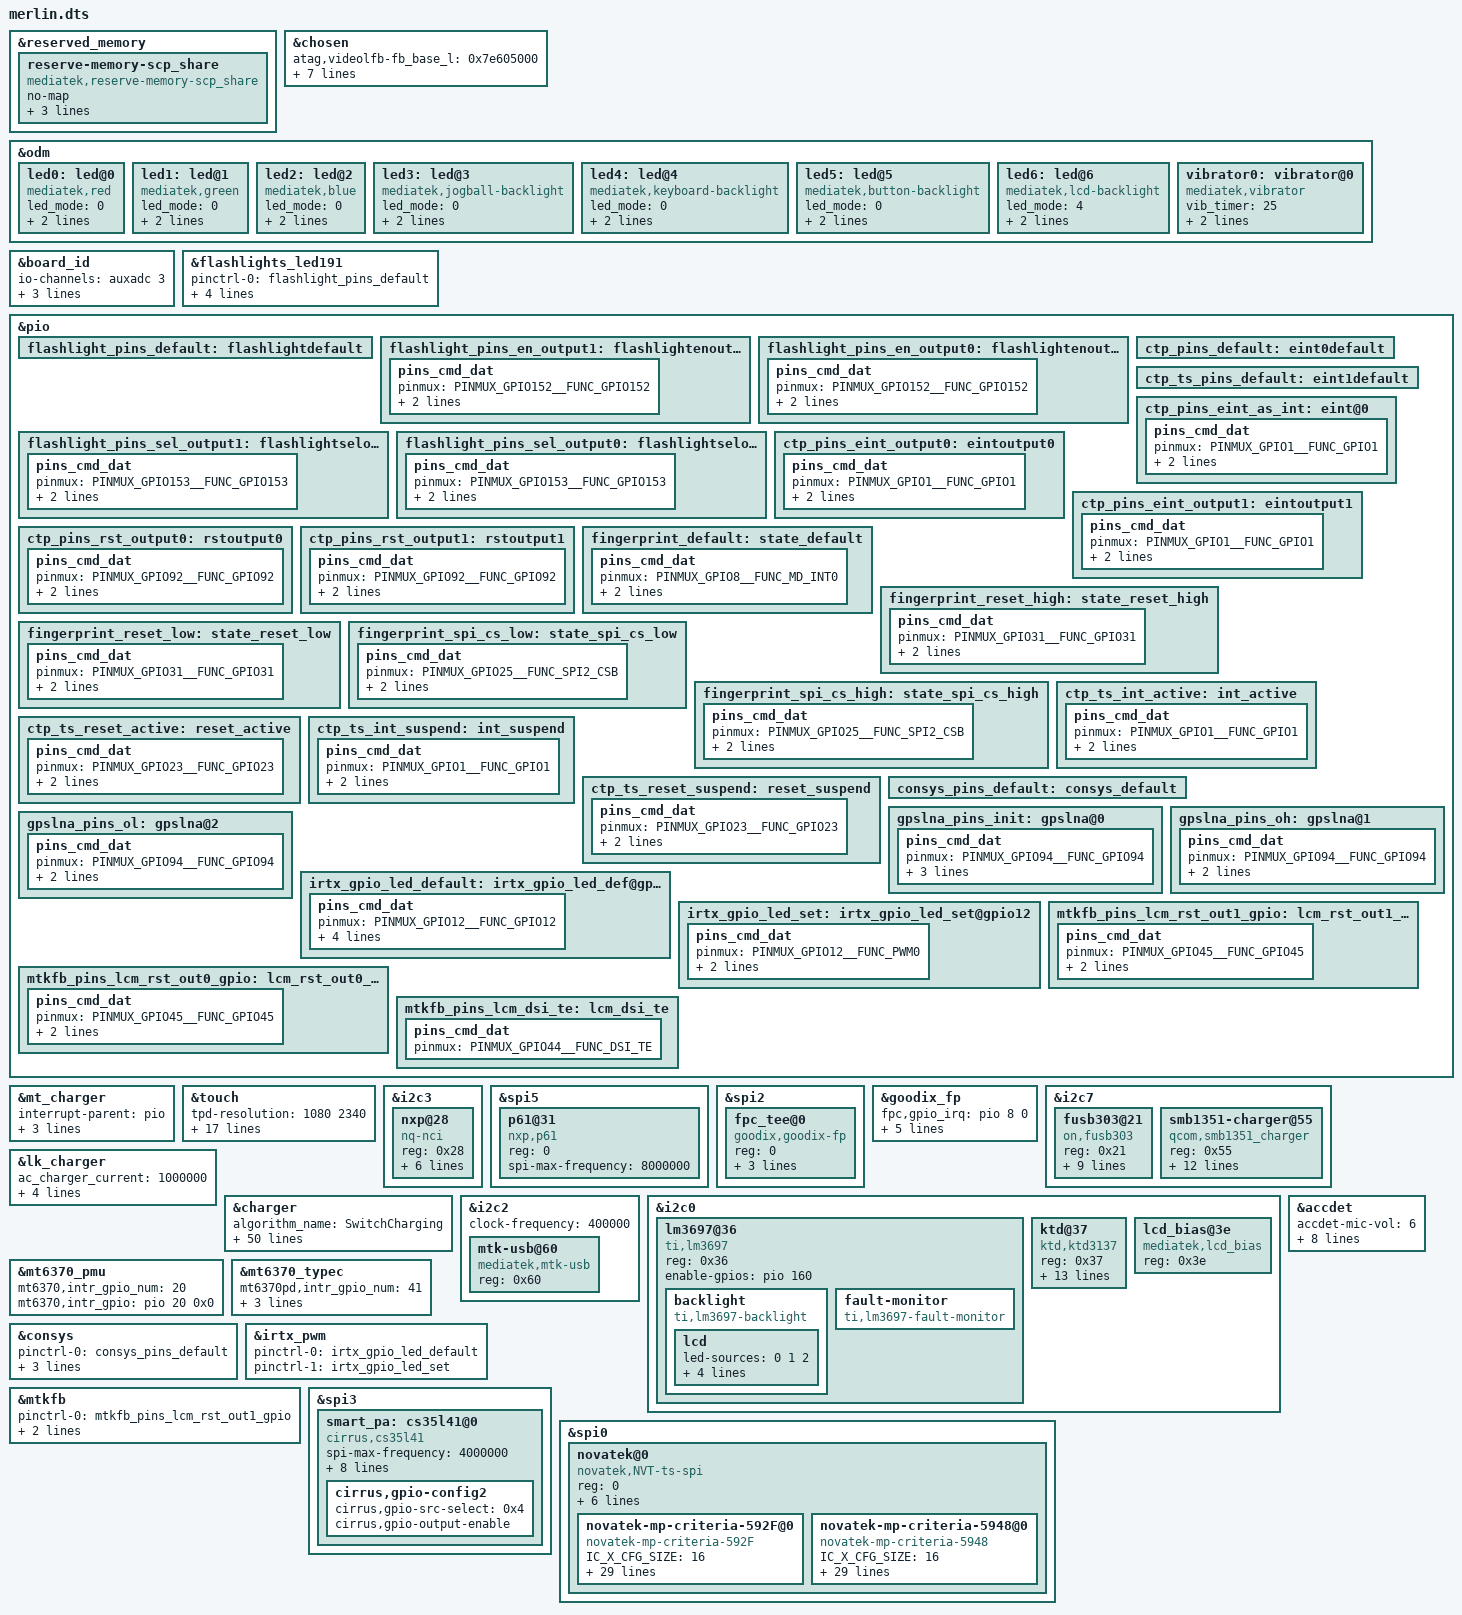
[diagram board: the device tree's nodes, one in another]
/*
 * Copyright (C) 2019 MediaTek Inc.
 *
 * This program is free software; you can redistribute it and/or modify
 * it under the terms of the GNU General Public License version 2 as
 * published by the Free Software Foundation.
 *
 * This program is distributed in the hope that it will be useful,
 * but WITHOUT ANY WARRANTY; without even the implied warranty of
 * MERCHANTABILITY or FITNESS FOR A PARTICULAR PURPOSE.
 * See http://www.gnu.org/licenses/gpl-2.0.html for more details.
 */

/dts-v1/;
/plugin/;
#include <dt-bindings/interrupt-controller/irq.h>
#include <dt-bindings/interrupt-controller/arm-gic.h>
#include <dt-bindings/pinctrl/mt6768-pinfunc.h>

&reserved_memory {
	reserve-memory-scp_share {
		compatible = "mediatek,reserve-memory-scp_share";
		no-map;
		size = <0 0x00d00000>;
		alignment = <0 0x1000000>;
		alloc-ranges = <0 0x40000000 0 0x50000000>;
	};
};

/* chosen */
&chosen {

	atag,videolfb-fb_base_l = <0x7e605000>;
	atag,videolfb-fb_base_h = <0x0>;
	atag,videolfb-islcmfound = <1>;
	atag,videolfb-islcm_inited = <0>;
	atag,videolfb-fps= <6000>;
	atag,videolfb-vramSize= <0x017e8000>;
	atag,videolfb-lcmname=
		"hx83112b_fhdp_dsi_cmd_auo_rt5081_drv";
};

&odm {
	led0:led@0 {
		compatible = "mediatek,red";
		led_mode = <0>;
		data = <1>;
		pwm_config = <0 0 0 0 0>;
	};
	led1:led@1 {
		compatible = "mediatek,green";
		led_mode = <0>;
		data = <1>;
		pwm_config = <0 0 0 0 0>;
	};
	led2:led@2 {
		compatible = "mediatek,blue";
		led_mode = <0>;
		data = <1>;
		pwm_config = <0 0 0 0 0>;
	};
	led3:led@3 {
		compatible = "mediatek,jogball-backlight";
		led_mode = <0>;
		data = <1>;
		pwm_config = <0 0 0 0 0>;
	};
	led4:led@4 {
		compatible = "mediatek,keyboard-backlight";
		led_mode = <0>;
		data = <1>;
		pwm_config = <0 0 0 0 0>;
	};
	led5:led@5 {
		compatible = "mediatek,button-backlight";
		led_mode = <0>;
		data = <1>;
		pwm_config = <0 0 0 0 0>;
	};
	led6:led@6 {
		compatible = "mediatek,lcd-backlight";
		led_mode = <4>;
		data = <1>;
		pwm_config = <0 3 0 0 0>;
	};
	vibrator0:vibrator@0 {
		compatible = "mediatek,vibrator";
		vib_timer = <25>;
		vib_limit = <9>;
		vib_vol= <10>;
	};
};

&board_id {
	io-channels = <&auxadc 3>;
	io-channel-names = "board_id-channel";
	hw_id-gpios = <&pio 158 0>;
	board_id2-gpios = <&pio 5 0>;
	board_id3-gpios = <&pio 6 0>;
	status = "okay";
};
/*
&board_id {
	io-channels = <&auxadc 3>;
	io-channel-names = "board_id-channel";
	status = "okay";
};
*/

/* flashlight start */
&flashlights_led191 {
	pinctrl-names = "default", "hw_ch0_high",
		"hw_ch0_low", "hw_ch1_high",
		"hw_ch1_low";
	pinctrl-0 = <&flashlight_pins_default>;
	pinctrl-1 = <&flashlight_pins_en_output1>;
	pinctrl-2 = <&flashlight_pins_en_output0>;
	pinctrl-3 = <&flashlight_pins_sel_output1>;
	pinctrl-4 = <&flashlight_pins_sel_output0>;
	status = "okay";
};
&pio {
	flashlight_pins_default: flashlightdefault {
	};
	flashlight_pins_en_output1: flashlightenoutput1 {
		pins_cmd_dat {
			pinmux = <PINMUX_GPIO152__FUNC_GPIO152>;
			slew-rate = <1>;
			output-high;
		};
	};
	flashlight_pins_en_output0: flashlightenoutput0 {
		pins_cmd_dat {
			pinmux = <PINMUX_GPIO152__FUNC_GPIO152>;
			slew-rate = <1>;
			output-low;
		};
	};
	flashlight_pins_sel_output1: flashlightseloutput1 {
		pins_cmd_dat {
			pinmux = <PINMUX_GPIO153__FUNC_GPIO153>;
			slew-rate = <1>;
			output-high;
		};
	};
	flashlight_pins_sel_output0: flashlightseloutput0 {
		pins_cmd_dat {
			pinmux = <PINMUX_GPIO153__FUNC_GPIO153>;
			slew-rate = <1>;
			output-low;
		};
	};
};
/* flashlight end*/

&mt_charger {
	interrupt-parent = <&pio>;
	reverse-gpio = <&pio 91 0>;
	pinctrl-names = "reverse_high", "reverse_low";
	pinctrl-0 = <&reverse_high>;
	pinctrl-1 = <&reverse_low>;
};
/* TOUCH start */
&touch {
	tpd-resolution = <1080 2340>;
	use-tpd-button = <0>;
	tpd-key-num = <3>;
	tpd-key-local= <139 172 158 0>;
	tpd-key-dim-local = <90 883 100 40 230
				883 100 40 370 883 100 40 0 0 0 0>;
	tpd-max-touch-num = <10>;
	tpd-filter-enable = <0>;
	tpd-filter-pixel-density = <168>;
	tpd-filter-custom-prameters = <0 0 0 0 0 0 0 0 0 0 0 0>;
	tpd-filter-custom-speed = <0 0 0>;
	pinctrl-names = "default", "state_eint_as_int",
		"state_eint_output0", "state_eint_output1",
		"state_rst_output0", "state_rst_output1";
	pinctrl-0 = <&ctp_pins_default>;
	pinctrl-1 = <&ctp_pins_eint_as_int>;
	pinctrl-2 = <&ctp_pins_eint_output0>;
	pinctrl-3 = <&ctp_pins_eint_output1>;
	pinctrl-4 = <&ctp_pins_rst_output0>;
	pinctrl-5 = <&ctp_pins_rst_output1>;
	status = "okay";
};
&pio {
	ctp_pins_default: eint0default {
	};
	ctp_ts_pins_default: eint1default {
	};
	ctp_pins_eint_as_int: eint@0 {
		pins_cmd_dat {
			pinmux = <PINMUX_GPIO1__FUNC_GPIO1>;
			slew-rate = <0>;
			bias-disable;
		};
	};
	ctp_pins_eint_output0: eintoutput0 {
		pins_cmd_dat {
			pinmux = <PINMUX_GPIO1__FUNC_GPIO1>;
			slew-rate = <1>;
			output-low;
		};
	};
	ctp_pins_eint_output1: eintoutput1 {
		pins_cmd_dat {
			pinmux = <PINMUX_GPIO1__FUNC_GPIO1>;
			slew-rate = <1>;
			output-high;
	};
	};
	ctp_pins_rst_output0: rstoutput0 {
		pins_cmd_dat {
				pinmux = <PINMUX_GPIO92__FUNC_GPIO92>;
				slew-rate = <1>;
				output-low;
			};
	};
	ctp_pins_rst_output1: rstoutput1 {
		pins_cmd_dat {
				pinmux = <PINMUX_GPIO92__FUNC_GPIO92>;
				slew-rate = <1>;
				output-high;
		};
	};

};
/* TOUCH end */
&i2c3 {
	status = "okay";
	nxp@28 {
		compatible = "nq-nci";
		reg = <0x28>;
		nq-irq = <&pio 9 0x00>;
		interrupt-parent = <&pio>;
		interrupts = <9 IRQ_TYPE_LEVEL_HIGH 9 0>;
		nq-ven = <&pio 159 0x0>;
		nq-firm = <&pio 17 0x0>;
		nq-clkreq = <&pio 11 0x0>;
		//nq-esepwr = <&tlmm 42 0x00>;
		interrupt-names = "irq_nfc";
	};

};
/* add goodix fingerprint start*/

&spi5 {
	#address-cells = <1>;
	#size-cells = <0>;
	p61@31 {
		compatible = "nxp,p61";
		reg = <0>;
		spi-max-frequency = <8000000>;
		status = "okay";
	};
};


&spi2 {
	status = "ok";
	#address-cells = <1>;
	#size-cells = <0>;
	fpc_tee@0 {
		compatible = "goodix,goodix-fp";
		reg = <0>;
		fpc,enable-wakeup;
		spi-max-frequency = <10000000>;
		netlink-event = <30>;
		status = "okay";
	};
};

&goodix_fp {
	fpc,gpio_irq = <&pio 8 0>;
	pinctrl-names = "default", "reset_high", "reset_low", "spi_cs_low", "spi_cs_high";
	pinctrl-0 = <&fingerprint_default>;
	pinctrl-1 = <&fingerprint_reset_high>;
	pinctrl-2 = <&fingerprint_reset_low>;
	pinctrl-3 = <&fingerprint_spi_cs_low>;
	pinctrl-4 = <&fingerprint_spi_cs_high>;
	status = "okay";
};

&pio {
	fingerprint_default: state_default {
		pins_cmd_dat {
			pinmux = <PINMUX_GPIO8__FUNC_MD_INT0>;
			slew-rate = <0>;
			bias-disable;
		};
	};
	fingerprint_reset_high: state_reset_high {
		pins_cmd_dat {
			pinmux = <PINMUX_GPIO31__FUNC_GPIO31>;
			slew-rate = <1>;
			output-high;
		};
	};
	fingerprint_reset_low: state_reset_low {
		pins_cmd_dat {
			pinmux = <PINMUX_GPIO31__FUNC_GPIO31>;
			slew-rate = <1>;
			output-low;
		};
	};

	fingerprint_spi_cs_low: state_spi_cs_low {
		pins_cmd_dat {
			pinmux = <PINMUX_GPIO25__FUNC_SPI2_CSB>;
			slew-rate = <1>;
			output-low;
		};
	};
	fingerprint_spi_cs_high: state_spi_cs_high {
		pins_cmd_dat {
			pinmux = <PINMUX_GPIO25__FUNC_SPI2_CSB>;
			slew-rate = <1>;
			output-high;
		};
	};

	ctp_ts_int_active: int_active {
		pins_cmd_dat {
			pinmux = <PINMUX_GPIO1__FUNC_GPIO1>;
			slew-rate = <0>;
			bias-pull-up = <11>;
		};
	};
	ctp_ts_reset_active: reset_active {
		pins_cmd_dat {
			pinmux = <PINMUX_GPIO23__FUNC_GPIO23>;
			slew-rate = <1>;
			output-high;
		};
	};
	ctp_ts_int_suspend: int_suspend {
		pins_cmd_dat {
			pinmux = <PINMUX_GPIO1__FUNC_GPIO1>;
			slew-rate = <1>;
			output-low;
		};
	};
	ctp_ts_reset_suspend: reset_suspend {
		pins_cmd_dat {
			pinmux = <PINMUX_GPIO23__FUNC_GPIO23>;
			slew-rate = <1>;
			output-low;
		};
	};
};
/* add goodix fingerprint end*/

&i2c7 {
	fusb303@21 {
		status = "ok";
		compatible = "on,fusb303";
		reg = <0x21>;
		interrupt-parent = <&pio>;
		interrupts = <41 0x2>;
		fusb303,int-gpio = <&pio 41 0>;
		fusb303,init-mode = <20>;			/* trysnk, DRP */
		fusb303,host-current = <2>;			/* 180uA host current */
		fusb303,drp-toggle-time =  <1>;			/* 70ms */
		fusb303,drp-duty-time = <0>;			/* 60 duty time */
		fusb303,autosink-threshold = <1>;		/* 3P1V */
		fusb303,cc-debounce-time = <3>;			/* 150ms */
	};
};


&i2c7 {
	smb1351-charger@55 {
		compatible = "qcom,smb1351_charger";
		reg = <0x55>;
		interrupt-parent = <&pio>;
		interrupts = <20 IRQ_TYPE_EDGE_FALLING 20 0>;
		qcom,recharge-disabled;
		qcom,bc12_supported;
		/* qcom,smb1351_susp = <&pio 21 0x0>; */
		/* mi,connect_therm = <&pio 127 0x0>; */

		charger_name = "primary_chg";
		/*charger_name = "secondary_chg";*/
		ichg = <1800000>; /* uA */
		mivr = <4500000>; /* uV */
		cv = <4396000>; /* uV */
		ieoc = <200000>; /* uA */
		safety_timer = <12>; /* hour */
		en_st; /* safety timer */
		/* en_te; */
		en_wdt;
	};

};
&lk_charger  {
	/* charging current */
	ac_charger_current = <1000000>;
	non_std_ac_charger_current = <1000000>;

	/* battery temperature protection */
	temp_t4_threshold = <60>;
	temp_t3_threshold = <45>;
	temp_t1_threshold = <0>;
};

&charger {
	algorithm_name = "SwitchCharging";

	set_cap_delay = <10>;
	enable_sw_jeita;
	battery_cv = <4460000>;
	usb_charger_current_suspend = <0>;
	usb_charger_current_unconfigured = <70000>;
	usb_charger_current_configured = <500000>;
	usb_charger_current = <500000>;
	ac_charger_current = <2050000>;
	ac_charger_input_current = <2050000>;
	non_std_ac_charger_current = <1000000>;
	charging_host_charger_current = <1500000>;
	apple_1_0a_charger_current = <650000>;
	apple_2_1a_charger_current = <800000>;
	ta_ac_charger_current = <2050000>;
	hvdcp_charger_current = <3000000>;

	pd_vbus_upper_bound = <9000000>;


	/* sw jeita */
	jeita_temp_above_t4_cv = <4100000>;
	jeita_temp_t3_to_t4_cv = <4100000>;
	jeita_temp_t2_to_t3_cv = <4460000>;
	jeita_temp_t1_to_t2_cv = <4460000>;
	jeita_temp_t0_to_t1_cv = <4460000>;
	jeita_temp_below_t0_cv = <4460000>;


	jeita_temp_t3_to_t4_cc = <2500000>;
	jeita_temp_t2_to_t3_cc = <3000000>;
	jeita_temp_t1_to_t2_cc = <2500000>;
	jeita_temp_t0_to_t1_cc = <1000000>;

	temp_t4_thres = <60>;
	temp_t4_thres_minus_x_degree = <58>;
	temp_t3_thres = <45>;
	temp_t3_thres_minus_x_degree = <43>;
	temp_t2_thres = <10>;
	temp_t2_thres_plus_x_degree = <8>;
	temp_t1_thres = <5>;
	temp_t1_thres_plus_x_degree = <4>;
	temp_t0_thres = <0>;
	temp_t0_thres_plus_x_degree = <0>;
	temp_neg_10_thres = <0>;

	/* battery temperature protection */
	enable_min_charge_temp;
	min_charge_temp = <0>;
	min_charge_temp_plus_x_degree = <2>;
	max_charge_temp = <60>;
	max_charge_temp_minus_x_degree = <58>;

	qcom,thermal-mitigation-dcp
		= <1800000 1800000 1800000 1800000 1800000 1800000 1800000
		1800000 1800000 1800000 1800000 1800000 1600000 1400000
		1200000 1000000>;
	qcom,thermal-mitigation-qc3
		= <2700000 2570000 2400000 2270000 2120000 1965000 1820000
		1650000 1500000 1375000 1225000 1100000 975000 825000
		675000 475000>;
	qcom,thermal-mitigation-qc2
		= <1625000 1625000 1625000 1625000 1625000 1525000 1425000
		1325000 1225000 1125000 1025500 925000 825000 725000
		625000 525000>;
	qcom,thermal-mitigation-pd-base
		= <3000000 2800000 2600000 2400000 2200000 2000000 1800000
		1600000 1600000 1400000 1200000 1100000 1000000 900000
		752500 525000>;
};




&i2c2 {
	clock-frequency = <400000>;

	mtk-usb@60 {
		compatible = "mediatek,mtk-usb";
		reg = <0x60>;
		status = "okay";
	};
};

&i2c0 {
	lm3697@36 {
		compatible = "ti,lm3697";
		reg = <0x36>;

		status = "okay";
		enable-gpios = <&pio 160 0>;

		backlight {
			compatible = "ti,lm3697-backlight";

			lcd {
				led-sources = <0 1 2>;
				ramp-up-msec = <200>;
				ramp-down-msec = <200>;
				pwm-period = <0>;
				default-brightness-level = <255>;
			};
		};
		fault-monitor {
			compatible = "ti,lm3697-fault-monitor";
		};
	};

	ktd@37 {
	compatible = "ktd,ktd3137";
	reg = <0x37>;
	status = "okay";
        /*ktd,pwm-mode; */
	ktd,using-lsb = <1>;
	ktd,pwm-frequency = <100>;
	ktd,bl-fscal-led = <0x98>;/*default 20.2mA*/
	ktd,turn-on-ramp = <0>;
	ktd,turn-off-ramp = <0>;
	ktd,pwm-trans-dim = <0>;
	ktd,i2c-trans-dim = <0>;
	ktd,bl-channel = <2>;
	ktd,ovp-level = <32>;/*default 32v*/
	ktd,switching-frequency = <1000>; /*default 1000kHz*/
	ktd,inductor-current = <2600>; //default 2600mA
	ktd,linear_ramp = <1>; /*default is exponential*/
	ktd,linear_backlight = <1>; /*default is exponential*/
    };

	lcd_bias@3e {
		compatible = "mediatek,lcd_bias";
		reg = <0x3e>;
		status = "okay";
	};
};

/* accdet start */
&accdet {
	/* accdet micbias voltage: 0x07,2.7v;0x05,2.5v;0x02,1.9v */
	accdet-mic-vol = <6>;
	headset-mode-setting = <0x500 0x500 1 0x1f0 0x800 0x800 0x20 0x44>;
	accdet-plugout-debounce = <1>;
	/*1:ACC mode, 2:low cost without in bias, 6:low cost with in bias*/
	accdet-mic-mode = <1>;
	/* eint_level_trigger: 8,LEVEL_LOW(DEF) ;4,LV_HIGH;others,LV_LOW */
	headset-eint-level-pol = <8>;
	/*0--MD_MAX--UP_MAX--DW_MAX*/
	headset-three-key-threshold = <0 80 220 400>;
	headset-three-key-threshold-CDD = <0 121 192 600>;
	/*0--MD_MAX--VOICE_MAX--UP_MAX--DW_MAX*/
	headset-four-key-threshold = <0 58 121 192 400>;
	status = "okay";
};
/* accdet end */

&mt6370_pmu {
	mt6370,intr_gpio_num = <20>; /* direct defined GPIO num */
	mt6370,intr_gpio = <&pio 20 0x0>;
};
&mt6370_typec {
	mt6370pd,intr_gpio_num = <41>; /* direct defined GPIO num */
	mt6370pd,intr_gpio = <&pio 41 0x0>;
	mt6370pd,usb_switch_gpio_num = <91>; /* direct defined GPIO num */
	mt6370pd,usb_switch_gpio = <&pio 91 0x0>;
};

/* CONSYS GPIO standardization */
&pio {
	consys_pins_default: consys_default {
	};
	gpslna_pins_init: gpslna@0 {
		pins_cmd_dat {
			pinmux = <PINMUX_GPIO94__FUNC_GPIO94>;
			slew-rate = <0>;
			bias-disable;
			output-low;
		};
	};
	gpslna_pins_oh: gpslna@1 {
		pins_cmd_dat {
			pinmux = <PINMUX_GPIO94__FUNC_GPIO94>;
			slew-rate = <1>;
			output-high;
		};
	};
	gpslna_pins_ol: gpslna@2 {
		pins_cmd_dat {
			pinmux = <PINMUX_GPIO94__FUNC_GPIO94>;
			slew-rate = <1>;
			output-low;
		};
	};
};
&consys {
	pinctrl-names = "default", "gps_lna_state_init",
		"gps_lna_state_oh", "gps_lna_state_ol";
	pinctrl-0 = <&consys_pins_default>;
	pinctrl-1 = <&gpslna_pins_init>;
	pinctrl-2 = <&gpslna_pins_oh>;
	pinctrl-3 = <&gpslna_pins_ol>;
	status = "okay";
};
/* CONSYS end */

/* IRTX GPIO Start */
&irtx_pwm {
	pinctrl-names = "irtx_gpio_led_default", "irtx_gpio_led_set";
	pinctrl-0 = <&irtx_gpio_led_default>;
	pinctrl-1 = <&irtx_gpio_led_set>;
	status = "okay";
};
&pio {
	/* IRTX GPIO Settings -Start */
	/* default: GPIO0, output, high */
	irtx_gpio_led_default:irtx_gpio_led_def@gpio12 {
		pins_cmd_dat {
			pinmux = <PINMUX_GPIO12__FUNC_GPIO12>;
			slew-rate = <1>;
			bias-disable;
			output-low;
			input-schmitt-enable = <0>;
		};
	};

	irtx_gpio_led_set:irtx_gpio_led_set@gpio12 {
		pins_cmd_dat {
			pinmux = <PINMUX_GPIO12__FUNC_PWM0>;
			slew-rate = <1>;
			output-high;
		};
	};
}; /* IRTX GPIO Settings -End */

/* DISPSYS GPIO standardization */
&pio {
	mtkfb_pins_lcm_rst_out1_gpio: lcm_rst_out1_gpio {
		pins_cmd_dat {
			pinmux = <PINMUX_GPIO45__FUNC_GPIO45>;
			slew-rate = <1>;
			output-high;
		};
	};

	mtkfb_pins_lcm_rst_out0_gpio: lcm_rst_out0_gpio {
		pins_cmd_dat {
			pinmux = <PINMUX_GPIO45__FUNC_GPIO45>;
			slew-rate = <1>;
			output-low;
		};
	};

	mtkfb_pins_lcm_dsi_te: lcm_dsi_te {
		pins_cmd_dat {
			pinmux = <PINMUX_GPIO44__FUNC_DSI_TE>;
		};
	};
};

&mtkfb {
	pinctrl-names =
		"lcm_rst_out1_gpio", "lcm_rst_out0_gpio",
		"mode_te_te";
	pinctrl-0 = <&mtkfb_pins_lcm_rst_out1_gpio>;
	pinctrl-1 = <&mtkfb_pins_lcm_rst_out0_gpio>;
	pinctrl-2 = <&mtkfb_pins_lcm_dsi_te>;
	status = "okay";
};

&spi3 {
    status = "okay";
    smart_pa:cs35l41@0 {
	       compatible = "cirrus,cs35l41";
		spi-max-frequency = <4000000>;
		reg = <0>;
		reset-gpio = <&pio 79 0>;
		interrupt-parent = <&gpio>;
		interrupts = <80 8>;
		irq-gpio = <&pio 80 0>;
		cirrus,boost-peak-milliamp = <4500>;
		cirrus,boost-ind-nanohenry = <1000>;
		cirrus,boost-cap-microfarad = <15>;
		cirrus,gpio-config2 {
		    cirrus,gpio-src-select = <0x4>;
		    cirrus,gpio-output-enable;
		    };
	   };
};

&spi0 {
	status = "ok";


	/* Novatek device tree node */
	novatek@0 {
		compatible = "novatek,NVT-ts-spi","focaltech,fts";
		reg = <0>; //Same as CS ID
		status = "ok";

		spi-max-frequency = <8000000>;
		//4800000,9600000,15000000,19200000;ft8719 max limit 8M
		novatek,reset-gpio = <&pio 92 0x00>;
		novatek,irq-gpio = <&pio 1 0x2001>;

		/* 525 */
		//novatek,swrst-n8-addr = <0x01F01A>;

		/* 672A, 525B, 675, 526 */
		novatek,swrst-n8-addr = <0x03F0FE>;
		novatek,spi-rd-fast-addr = <0x03F310>;

		/* MP */
		novatek,mp-support-dt;

		novatek-mp-criteria-592F@0 {
			#address-cells = <1>;
			#size-cells = <0>;
			compatible = "novatek-mp-criteria-592F";

			/* MP Config */
			IC_X_CFG_SIZE = <16>;
			IC_Y_CFG_SIZE = <36>;
			IC_KEY_CFG_SIZE = <4>;
			X_Channel = <16>;
			Y_Channel = <36>;
			AIN_X = <0 1 2 3 4 5 6 7 8 9 10 11 12 13 14 15>;
			AIN_Y = <0 1 2 3 4 5 6 7 8 9 10 11 12 13 14 15 16 17
						18 19 20 21 22 23 24 25 26 27 28 29 30 31 32 33 34 35>;
			AIN_KEY = <0 1 2 0xFF>;

			/* MP Criteria */
			PS_Config_Lmt_Short_Rawdata_P = <
				14000	14000	14000	14000	14000	14000	14000	14000	14000	14000	14000	14000	14000	14000	14000	14000
				14000	14000	14000	14000	14000	14000	14000	14000	14000	14000	14000	14000	14000	14000	14000	14000
				14000	14000	14000	14000	14000	14000	14000	14000	14000	14000	14000	14000	14000	14000	14000	14000
				14000	14000	14000	14000	14000	14000	14000	14000	14000	14000	14000	14000	14000	14000	14000	14000
				14000	14000	14000	14000	14000	14000	14000	14000	14000	14000	14000	14000	14000	14000	14000	14000
				14000	14000	14000	14000	14000	14000	14000	14000	14000	14000	14000	14000	14000	14000	14000	14000
				14000	14000	14000	14000	14000	14000	14000	14000	14000	14000	14000	14000	14000	14000	14000	14000
				14000	14000	14000	14000	14000	14000	14000	14000	14000	14000	14000	14000	14000	14000	14000	14000
				14000	14000	14000	14000	14000	14000	14000	14000	14000	14000	14000	14000	14000	14000	14000	14000
				14000	14000	14000	14000	14000	14000	14000	14000	14000	14000	14000	14000	14000	14000	14000	14000
				14000	14000	14000	14000	14000	14000	14000	14000	14000	14000	14000	14000	14000	14000	14000	14000
				14000	14000	14000	14000	14000	14000	14000	14000	14000	14000	14000	14000	14000	14000	14000	14000
				14000	14000	14000	14000	14000	14000	14000	14000	14000	14000	14000	14000	14000	14000	14000	14000
				14000	14000	14000	14000	14000	14000	14000	14000	14000	14000	14000	14000	14000	14000	14000	14000
				14000	14000	14000	14000	14000	14000	14000	14000	14000	14000	14000	14000	14000	14000	14000	14000
				14000	14000	14000	14000	14000	14000	14000	14000	14000	14000	14000	14000	14000	14000	14000	14000
				14000	14000	14000	14000	14000	14000	14000	14000	14000	14000	14000	14000	14000	14000	14000	14000
				14000	14000	14000	14000	14000	14000	14000	14000	14000	14000	14000	14000	14000	14000	14000	14000
				14000	14000	14000	14000	14000	14000	14000	14000	14000	14000	14000	14000	14000	14000	14000	14000
				14000	14000	14000	14000	14000	14000	14000	14000	14000	14000	14000	14000	14000	14000	14000	14000
				14000	14000	14000	14000	14000	14000	14000	14000	14000	14000	14000	14000	14000	14000	14000	14000
				14000	14000	14000	14000	14000	14000	14000	14000	14000	14000	14000	14000	14000	14000	14000	14000
				14000	14000	14000	14000	14000	14000	14000	14000	14000	14000	14000	14000	14000	14000	14000	14000
				14000	14000	14000	14000	14000	14000	14000	14000	14000	14000	14000	14000	14000	14000	14000	14000
				14000	14000	14000	14000	14000	14000	14000	14000	14000	14000	14000	14000	14000	14000	14000	14000
				14000	14000	14000	14000	14000	14000	14000	14000	14000	14000	14000	14000	14000	14000	14000	14000
				14000	14000	14000	14000	14000	14000	14000	14000	14000	14000	14000	14000	14000	14000	14000	14000
				14000	14000	14000	14000	14000	14000	14000	14000	14000	14000	14000	14000	14000	14000	14000	14000
				14000	14000	14000	14000	14000	14000	14000	14000	14000	14000	14000	14000	14000	14000	14000	14000
				14000	14000	14000	14000	14000	14000	14000	14000	14000	14000	14000	14000	14000	14000	14000	14000
				14000	14000	14000	14000	14000	14000	14000	14000	14000	14000	14000	14000	14000	14000	14000	14000
				14000	14000	14000	14000	14000	14000	14000	14000	14000	14000	14000	14000	14000	14000	14000	14000
				14000	14000	14000	14000	14000	14000	14000	14000	14000	14000	14000	14000	14000	14000	14000	14000
				14000	14000	14000	14000	14000	14000	14000	14000	14000	14000	14000	14000	14000	14000	14000	14000
				14000	14000	14000	14000	14000	14000	14000	14000	14000	14000	14000	14000	14000	14000	14000	14000
				14000	14000	14000	14000	14000	14000	14000	14000	14000	14000	14000	14000	14000	14000	14000	14000
				14008 14008 14008>;

			PS_Config_Lmt_Short_Rawdata_N = <
				11000	11000	11000	11000	11000	11000	11000	11000	11000	11000	11000	11000	11000	11000	11000	11000
				11000	11000	11000	11000	11000	11000	11000	11000	11000	11000	11000	11000	11000	11000	11000	11000
				11000	11000	11000	11000	11000	11000	11000	11000	11000	11000	11000	11000	11000	11000	11000	11000
				11000	11000	11000	11000	11000	11000	11000	11000	11000	11000	11000	11000	11000	11000	11000	11000
				11000	11000	11000	11000	11000	11000	11000	11000	11000	11000	11000	11000	11000	11000	11000	11000
				11000	11000	11000	11000	11000	11000	11000	11000	11000	11000	11000	11000	11000	11000	11000	11000
				11000	11000	11000	11000	11000	11000	11000	11000	11000	11000	11000	11000	11000	11000	11000	11000
				11000	11000	11000	11000	11000	11000	11000	11000	11000	11000	11000	11000	11000	11000	11000	11000
				11000	11000	11000	11000	11000	11000	11000	11000	11000	11000	11000	11000	11000	11000	11000	11000
				11000	11000	11000	11000	11000	11000	11000	11000	11000	11000	11000	11000	11000	11000	11000	11000
				11000	11000	11000	11000	11000	11000	11000	11000	11000	11000	11000	11000	11000	11000	11000	11000
				11000	11000	11000	11000	11000	11000	11000	11000	11000	11000	11000	11000	11000	11000	11000	11000
				11000	11000	11000	11000	11000	11000	11000	11000	11000	11000	11000	11000	11000	11000	11000	11000
				11000	11000	11000	11000	11000	11000	11000	11000	11000	11000	11000	11000	11000	11000	11000	11000
				11000	11000	11000	11000	11000	11000	11000	11000	11000	11000	11000	11000	11000	11000	11000	11000
				11000	11000	11000	11000	11000	11000	11000	11000	11000	11000	11000	11000	11000	11000	11000	11000
				11000	11000	11000	11000	11000	11000	11000	11000	11000	11000	11000	11000	11000	11000	11000	11000
				11000	11000	11000	11000	11000	11000	11000	11000	11000	11000	11000	11000	11000	11000	11000	11000
				11000	11000	11000	11000	11000	11000	11000	11000	11000	11000	11000	11000	11000	11000	11000	11000
				11000	11000	11000	11000	11000	11000	11000	11000	11000	11000	11000	11000	11000	11000	11000	11000
				11000	11000	11000	11000	11000	11000	11000	11000	11000	11000	11000	11000	11000	11000	11000	11000
				11000	11000	11000	11000	11000	11000	11000	11000	11000	11000	11000	11000	11000	11000	11000	11000
				11000	11000	11000	11000	11000	11000	11000	11000	11000	11000	11000	11000	11000	11000	11000	11000
				11000	11000	11000	11000	11000	11000	11000	11000	11000	11000	11000	11000	11000	11000	11000	11000
				11000	11000	11000	11000	11000	11000	11000	11000	11000	11000	11000	11000	11000	11000	11000	11000
				11000	11000	11000	11000	11000	11000	11000	11000	11000	11000	11000	11000	11000	11000	11000	11000
				11000	11000	11000	11000	11000	11000	11000	11000	11000	11000	11000	11000	11000	11000	11000	11000
				11000	11000	11000	11000	11000	11000	11000	11000	11000	11000	11000	11000	11000	11000	11000	11000
				11000	11000	11000	11000	11000	11000	11000	11000	11000	11000	11000	11000	11000	11000	11000	11000
				11000	11000	11000	11000	11000	11000	11000	11000	11000	11000	11000	11000	11000	11000	11000	11000
				11000	11000	11000	11000	11000	11000	11000	11000	11000	11000	11000	11000	11000	11000	11000	11000
				11000	11000	11000	11000	11000	11000	11000	11000	11000	11000	11000	11000	11000	11000	11000	11000
				11000	11000	11000	11000	11000	11000	11000	11000	11000	11000	11000	11000	11000	11000	11000	11000
				11000	11000	11000	11000	11000	11000	11000	11000	11000	11000	11000	11000	11000	11000	11000	11000
				11000	11000	11000	11000	11000	11000	11000	11000	11000	11000	11000	11000	11000	11000	11000	11000
				11000	11000	11000	11000	11000	11000	11000	11000	11000	11000	11000	11000	11000	11000	11000	11000
				10000 10000 10000>;

			PS_Config_Lmt_Open_Rawdata_P = <
				2899	65535	3065	3097	3064	3077	3046	3068	3037	3083	3053	3088	3070	3122	3055	2029
				2937	2764	3008	3049	3013	3035	3004	3021	3014	3061	3031	3068	3053	3103	3083	3079
				3083	2838	3020	3058	3022	3045	3011	3030	3023	3069	3037	3073	3061	3110	3086	3115
				3055	3054	3013	3051	3017	3040	3003	3022	3014	3056	3028	3063	3054	3100	3077	3126
				3049	3067	3027	3065	3025	3048	3014	3032	3018	3060	3035	3065	3058	3106	3077	3134
				3063	3073	3034	3070	3031	3055	3018	3039	3031	3072	3049	3082	3070	3114	3091	3134
				3072	3096	3054	3089	3049	3073	3036	3054	3046	3081	3060	3092	3079	3121	3097	3128
				3074	3098	3054	3091	3053	3078	3037	3055	3049	3081	3060	3093	3082	3120	3097	3114
				3101	3100	3054	3087	3046	3072	3031	3046	3042	3073	3054	3088	3073	3117	3089	3129
				3102	3108	3059	3092	3055	3081	3036	3056	3046	3069	3044	3087	3072	3110	3089	3122
				3091	3105	3053	3083	3042	3069	3026	3051	3056	3082	3055	3100	3086	3125	3100	3136
				3089	3103	3061	3092	3050	3077	3035	3059	3051	3074	3049	3094	3077	3115	3086	3136
				3075	3115	3070	3100	3060	3089	3045	3069	3073	3098	3075	3120	3101	3143	3115	3128
				3087	3116	3074	3103	3064	3091	3044	3075	3072	3094	3073	3119	3097	3136	3111	3136
				3093	3119	3084	3112	3070	3098	3055	3088	3086	3114	3089	3133	3111	3150	3119	3140
				3094	3106	3073	3103	3060	3086	3049	3077	3075	3100	3078	3124	3101	3141	3106	3120
				3101	3106	3075	3101	3058	3083	3046	3086	3086	3114	3092	3136	3112	3153	3114	3144
				3083	3105	3074	3101	3054	3082	3045	3083	3067	3091	3070	3117	3089	3129	3088	3150
				3075	3089	3058	3083	3045	3072	3030	3065	3089	3117	3098	3141	3112	3153	3112	3129
				3060	3106	3074	3103	3063	3089	3051	3088	3094	3116	3097	3141	3111	3149	3110	3136
				3059	3101	3068	3096	3056	3083	3044	3083	3068	3094	3072	3116	3091	3130	3087	3128
				3082	3079	3049	3074	3032	3063	3026	3059	3068	3097	3072	3115	3086	3128	3084	3117
				3069	3075	3045	3072	3030	3060	3026	3063	3060	3091	3068	3106	3077	3116	3079	3108
				3048	3074	3041	3068	3025	3053	3018	3060	3050	3083	3055	3096	3065	3103	3064	3102
				3039	3056	3025	3056	3013	3044	3011	3049	3041	3074	3048	3088	3059	3093	3056	3107
				3046	3049	3022	3050	3009	3041	3011	3046	3039	3073	3044	3084	3053	3088	3053	3091
				3030	3060	3030	3055	3014	3042	3013	3051	3048	3087	3053	3091	3061	3096	3060	3074
				3026	3028	2998	3026	2983	3014	2984	3022	3017	3055	3026	3067	3037	3073	3040	3061
				3027	3027	2998	3026	2983	3013	2984	3020	3003	3039	3008	3048	3020	3055	3018	3061
				2994	3008	2983	3009	2967	2999	2970	3006	2987	3023	2993	3035	3008	3040	3008	3037
				2993	2994	2966	2995	2954	2985	2957	2992	2983	3022	2994	3034	3007	3042	3011	3034
				2768	2976	2745	2978	2735	2969	2733	2974	2759	3002	2767	3011	2780	3018	2781	3009
				2759	2762	2736	2763	2725	2753	2724	2755	2754	2788	2763	2800	2774	2807	2776	2800
				2748	2767	2739	2764	2724	2752	2725	2757	2735	2768	2740	2781	2754	2787	2757	2827
				2678	2745	2713	2741	2701	2727	2703	2733	2706	2743	2719	2760	2733	2766	2735	2736
				1630	2717	2733	2763	2719	2748	2730	2753	2741	2773	2745	2788	2762	2791	2721	1675
				5120 5120 5120>;

			PS_Config_Lmt_Open_Rawdata_N = <
				1666	(-65535)	1762	1780	1761	1768	1751	1763	1746	1772	1754	1775	1765	1795	1756	1166
				1688	1589	1729	1752	1732	1744	1727	1736	1733	1760	1742	1763	1754	1784	1772	1770
				1772	1631	1735	1757	1737	1750	1730	1741	1738	1764	1746	1766	1760	1787	1773	1790
				1756	1755	1732	1754	1734	1747	1726	1737	1733	1757	1741	1760	1755	1781	1768	1797
				1752	1762	1740	1762	1738	1752	1733	1743	1735	1759	1744	1762	1757	1785	1768	1801
				1760	1766	1743	1765	1742	1756	1735	1746	1742	1765	1752	1771	1765	1789	1776	1801
				1765	1779	1755	1776	1752	1766	1745	1755	1751	1770	1759	1777	1770	1794	1780	1797
				1767	1781	1755	1776	1754	1769	1746	1756	1752	1770	1759	1778	1771	1793	1780	1789
				1782	1781	1755	1774	1751	1765	1742	1751	1749	1766	1755	1775	1766	1792	1776	1798
				1783	1787	1758	1777	1756	1770	1745	1757	1751	1764	1749	1774	1765	1787	1776	1795
				1776	1784	1754	1772	1749	1764	1739	1754	1757	1771	1756	1781	1773	1796	1781	1803
				1776	1784	1760	1777	1753	1768	1744	1758	1754	1767	1752	1779	1768	1790	1773	1803
				1768	1790	1765	1781	1759	1776	1750	1764	1766	1781	1768	1793	1782	1806	1790	1797
				1774	1791	1767	1784	1761	1776	1749	1768	1765	1779	1766	1792	1780	1803	1788	1803
				1778	1792	1773	1789	1765	1781	1756	1775	1773	1789	1776	1800	1788	1811	1792	1805
				1779	1785	1766	1784	1759	1773	1752	1768	1768	1781	1769	1795	1782	1806	1785	1793
				1782	1785	1768	1782	1757	1772	1751	1773	1773	1789	1777	1803	1789	1812	1789	1807
				1772	1784	1767	1782	1755	1771	1750	1772	1762	1776	1765	1792	1776	1798	1775	1811
				1768	1776	1757	1772	1750	1765	1741	1762	1776	1792	1781	1806	1789	1812	1789	1798
				1759	1785	1767	1784	1760	1776	1754	1775	1779	1791	1780	1806	1788	1810	1787	1803
				1758	1782	1763	1779	1757	1772	1749	1772	1763	1779	1765	1791	1776	1799	1774	1797
				1771	1770	1752	1767	1743	1760	1739	1758	1763	1780	1765	1790	1773	1797	1773	1792
				1764	1768	1750	1765	1741	1759	1739	1760	1759	1776	1763	1785	1768	1791	1770	1787
				1752	1767	1748	1763	1738	1754	1735	1759	1753	1772	1756	1779	1762	1784	1761	1783
				1746	1757	1738	1757	1732	1749	1730	1752	1748	1767	1752	1775	1758	1778	1757	1786
				1751	1752	1737	1753	1730	1748	1730	1751	1746	1766	1749	1773	1754	1775	1754	1776
				1741	1759	1741	1756	1733	1749	1732	1754	1752	1774	1754	1776	1760	1779	1759	1767
				1739	1741	1723	1739	1714	1733	1715	1737	1734	1756	1739	1762	1746	1766	1747	1760
				1740	1740	1723	1739	1714	1732	1715	1735	1726	1746	1729	1752	1735	1756	1735	1760
				1721	1729	1714	1730	1706	1724	1707	1727	1716	1738	1720	1744	1729	1747	1729	1746
				1720	1721	1705	1722	1697	1716	1700	1719	1714	1737	1721	1743	1728	1749	1730	1743
				1591	1711	1578	1711	1572	1706	1570	1709	1586	1725	1590	1730	1597	1735	1598	1730
				1586	1587	1573	1588	1566	1582	1565	1584	1583	1603	1588	1609	1595	1614	1595	1609
				1579	1590	1574	1589	1565	1581	1566	1584	1572	1591	1575	1598	1583	1602	1584	1624
				1539	1578	1560	1576	1552	1568	1554	1570	1555	1576	1562	1587	1570	1589	1572	1573
				937		1562	1570	1588	1562	1579	1569	1582	1576	1594	1578	1603	1587	1604	1564	962
				50 50 50>;
				
			PS_Config_Lmt_FW_Rawdata_P = <
				2166	65535	2130	2107	2115	2124	2099	2157	2157	2134	2139	2154	2157	2126	2149	2150
				2182	2142	2161	2184	2162	2127	2162	2142	2135	2155	2155	2127	2128	2124	2164	2126
				2185	2123	2168	2133	2139	2135	2137	2151	2085	2207	2162	2188	2153	2170	2177	2124
				2164	2139	2138	2123	2139	2131	2097	2124	2116	2182	2118	2110	2145	2118	2172	2112
				2165	2106	2149	2145	2107	2104	2114	2162	2091	2165	2174	2145	2154	2150	2124	2172
				2135	2164	2110	2134	2119	2154	2116	2135	2116	2099	2224	2111	2104	2092	2130	2133
				2097	2178	2114	2122	2119	2106	2106	2123	2177	2131	2145	2162	2164	2178	2170	2184
				2133	2176	2124	2146	2128	2146	2123	2143	2122	2139	2137	2112	2124	2118	2147	2207
				2124	2118	2131	2146	2107	2131	2133	2147	2176	2104	2146	2184	2174	2207	2166	2176
				2124	2153	2110	2141	2135	2126	2157	2138	2208	2138	2151	2151	2177	2174	2174	2176
				2146	2191	2123	2143	2141	2149	2158	2187	2169	2153	2103	2207	2203	2088	2205	2101
				2208	2187	2181	2160	2200	2214	2133	2161	2135	2143	2119	2164	2170	2137	2151	2122
				2093	2130	2134	2096	2112	2122	2138	2184	2216	2234	2178	2092	2088	2112	2134	2120
				2115	2134	2112	2158	2122	2147	2151	2120	2142	2155	2127	2168	2164	2170	2173	2203
				2106	2143	2242	2226	2234	2137	2126	2114	2185	2149	2137	2184	2199	2172	2154	2181
				2199	2147	2143	2126	2108	2126	2143	2120	2185	2168	2160	2097	2160	2161	2173	2139
				2107	2124	2150	2141	2108	2123	2139	2161	2142	2173	2182	2124	2139	2142	2112	2089
				2108	2158	2162	2182	2153	2174	2169	2110	2214	2178	2111	2064	2096	2073	2107	2205
				2147	2178	2164	2160	2185	2153	2131	2150	2185	2155	2124	2145	2147	2142	2155	2169
				2146	2123	2151	2131	2119	2114	2110	2153	2145	2058	2235	2228	2191	2204	2207	2189
				2120	2137	2155	2133	2126	2168	2151	2142	2177	2204	2196	2160	2220	2197	2181	2155
				2145	2138	2124	2119	2160	2157	2174	2189	2145	2158	2134	2139	2138	2118	2083	2119
				2143	2166	2172	2150	2151	2138	2116	2127	2104	2085	2108	2142	2134	2185	2149	2185
				2160	2166	2188	2162	2195	2135	2149	2201	2166	2137	2161	2145	2155	2138	2150	2149
				2180	2204	2188	2164	2215	2084	2093	2164	2145	2110	2151	2119	2112	2124	2119	2134
				2138	2120	2124	2120	2177	2147	2145	2164	2166	2184	2154	2165	2149	2155	2165	2173
				2181	2162	2143	2184	2153	2147	2120	2147	2145	2170	2096	2100	2161	2142	2182	2174
				2180	2151	2169	2124	2126	2169	2130	2123	2119	2155	2120	2118	2127	2141	2149	2170
				2154	2157	2162	2180	2154	2170	2126	2169	2178	2151	2166	2149	2162	2157	2111	2141
				2207	2134	2141	2161	2120	2166	2138	2157	2123	2135	2110	2160	2143	2162	2135	2127
				2128	2216	2191	2192	2169	2177	2154	2158	2193	2205	2174	2169	2164	2195	2134	2133
				2177	2184	2145	2207	2131	2130	2150	2158	2149	2189	2134	2157	2154	2155	2150	2097
				2166	2178	2133	2141	2118	2178	2176	2157	2131	2162	2122	2160	2141	2161	2130	2161
				2174	2146	2147	2111	2149	2200	2139	2138	2147	2143	2138	2176	2177	2142	2177	2153
				2107	2147	2176	2196	2182	2141	2137	2104	2142	2096	2085	2077	2118	2164	2150	2155
				2188	2104	2135	2089	2099	2097	2147	2164	2160	2137	2116	2124	2124	2155	2155	2188
				2560 2560 2560>;

			PS_Config_Lmt_FW_Rawdata_N = <
				1043	(-65535)	1025	1014	1018	1023	1010	1038	1038	1027	1030	1037	1038	1023	1034	1035
				1051	1031	1040	1051	1041	1024	1041	1031	1028	1038	1038	1024	1025	1023	1041	1023
				1052	1022	1043	1027	1030	1028	1028	1036	1004	1062	1041	1053	1036	1045	1048	1023
				1041	1030	1029	1022	1030	1026	1010	1023	1019	1051	1019	1015	1032	1019	1045	1017
				1042	1014	1034	1032	1014	1013	1017	1041	1006	1042	1047	1032	1037	1035	1023	1045
				1028	1041	1015	1027	1020	1037	1019	1028	1019	1010	1071	1016	1013	1007	1025	1027
				1010	1049	1017	1021	1020	1014	1014	1022	1048	1026	1032	1041	1041	1049	1045	1051
				1027	1047	1023	1033	1025	1033	1022	1032	1021	1030	1028	1017	1023	1019	1034	1062
				1023	1019	1026	1033	1014	1026	1027	1034	1047	1013	1033	1051	1047	1062	1043	1047
				1023	1036	1015	1030	1028	1023	1038	1029	1063	1029	1036	1036	1048	1047	1047	1047
				1033	1054	1022	1032	1030	1034	1039	1053	1044	1036	1012	1062	1060	1005	1062	1012
				1063	1053	1050	1040	1059	1066	1027	1040	1028	1032	1020	1041	1045	1028	1036	1021
				1008	1025	1027	1009	1017	1021	1029	1051	1067	1075	1049	1007	1005	1017	1027	1021
				1018	1027	1017	1039	1021	1034	1036	1021	1031	1038	1024	1043	1041	1045	1046	1060
				1014	1032	1079	1071	1075	1028	1023	1017	1052	1034	1028	1051	1058	1045	1037	1050
				1058	1034	1032	1023	1015	1023	1032	1021	1052	1043	1040	1010	1040	1040	1046	1030
				1014	1023	1035	1030	1015	1022	1030	1040	1031	1046	1051	1023	1030	1031	1017	1006
				1015	1039	1041	1051	1036	1047	1044	1015	1066	1049	1016	993	1009	998	1014	1062
				1034	1049	1041	1040	1052	1036	1026	1035	1052	1038	1023	1032	1034	1031	1038	1044
				1033	1022	1036	1026	1020	1017	1015	1036	1032	991	1076	1073	1054	1061	1062	1054
				1021	1028	1038	1027	1023	1043	1036	1031	1048	1061	1057	1040	1069	1058	1050	1038
				1032	1029	1023	1020	1040	1038	1047	1054	1032	1039	1027	1030	1029	1019	1002	1020
				1032	1043	1045	1035	1036	1029	1019	1024	1013	1004	1015	1031	1027	1052	1034	1052
				1040	1043	1053	1041	1056	1028	1034	1060	1043	1028	1040	1032	1038	1029	1035	1034
				1049	1061	1053	1041	1066	1003	1008	1041	1032	1015	1036	1020	1017	1023	1020	1027
				1029	1021	1023	1021	1048	1034	1032	1041	1043	1051	1037	1042	1034	1038	1042	1046
				1050	1041	1032	1051	1036	1034	1021	1034	1032	1045	1009	1011	1040	1031	1051	1047
				1049	1036	1044	1023	1023	1044	1025	1022	1020	1038	1021	1019	1024	1030	1034	1045
				1037	1038	1041	1049	1037	1045	1023	1044	1049	1036	1043	1034	1041	1038	1016	1030
				1062	1027	1030	1040	1021	1043	1029	1038	1022	1028	1015	1040	1032	1041	1028	1024
				1025	1067	1054	1055	1044	1048	1037	1039	1056	1062	1047	1044	1041	1056	1027	1027
				1048	1051	1032	1062	1026	1025	1035	1039	1034	1054	1027	1038	1037	1038	1035	1010
				1043	1049	1027	1030	1019	1049	1047	1038	1026	1041	1021	1040	1030	1040	1025	1040
				1047	1033	1034	1016	1034	1059	1030	1029	1034	1032	1029	1047	1048	1031	1048	1036
				1014	1034	1047	1057	1051	1030	1028	1013	1031	1009	1004	1000	1019	1041	1035	1038
				1053	1013	1028	1006	1010	1010	1034	1041	1040	1028	1019	1023	1023	1038	1038	1053
				240 240 240>;

			PS_Config_Lmt_FW_CC_P = <
				107	65535	119	119	119	119	119	119	122	122	121	120	120	119	119	105
				120	107	105	105	106	106	105	106	112	112	110	109	109	109	109	109
				125	106	105	105	105	105	105	105	109	109	107	106	106	106	105	107
				112	107	106	106	106	106	106	106	110	107	107	107	107	107	107	111
				110	107	106	106	105	106	106	106	109	107	106	105	105	105	105	107
				111	109	107	107	107	107	107	107	111	110	110	109	109	109	109	110
				110	106	105	105	105	105	105	105	109	107	107	106	106	106	105	109
				112	107	107	107	107	107	107	107	110	109	110	107	107	107	107	110
				110	107	107	107	106	107	107	107	109	109	109	106	106	107	106	110
				112	109	107	107	107	107	107	107	110	110	110	107	107	107	107	109
				110	106	105	105	105	105	106	106	110	109	109	106	106	107	106	110
				111	105	105	106	105	105	106	107	107	107	107	105	105	105	105	111
				110	106	105	106	105	106	106	107	109	109	109	109	109	109	107	109
				110	107	107	109	109	109	109	110	110	110	110	109	109	107	107	110
				110	105	105	105	105	106	106	109	106	107	107	105	105	106	105	110
				111	107	107	107	107	107	107	110	109	109	109	109	107	107	107	111
				109	107	107	107	107	107	107	109	109	109	107	107	107	107	107	110
				111	107	107	107	107	107	109	110	110	110	110	109	109	109	109	111
				110	105	105	105	105	105	106	106	107	107	106	106	106	106	105	110
				110	107	107	107	107	107	109	110	110	110	109	107	107	107	107	112
				109	106	106	106	106	107	107	107	110	109	107	107	107	106	106	110
				110	109	109	109	109	109	109	109	111	110	110	109	109	110	110	112
				110	106	105	106	105	106	107	107	110	107	107	106	107	106	106	112
				111	107	107	107	107	109	109	110	110	109	107	109	107	107	107	114
				109	106	106	107	106	107	107	109	109	109	107	107	109	107	107	112
				111	109	109	109	109	110	110	111	110	110	109	110	109	110	110	112
				110	106	105	105	105	107	107	107	107	107	107	107	107	107	107	112
				112	107	107	107	107	110	109	110	109	109	109	109	109	109	109	115
				109	107	107	107	107	109	109	110	106	107	106	106	107	107	109	115
				110	110	110	109	109	111	110	111	109	109	109	109	109	109	110	115
				111	106	105	105	105	106	106	107	107	107	107	107	107	107	110	114
				112	109	107	107	107	110	109	110	107	107	107	109	109	110	110	116
				107	107	107	107	106	107	107	110	106	106	107	106	107	107	110	112
				111	109	109	110	109	110	111	111	109	109	109	110	109	110	111	127
				110	106	105	105	105	107	109	109	105	105	106	106	106	106	109	110
				105	119	117	119	119	121	122	122	120	119	120	120	120	120	122	112
				314 314 314>;

			PS_Config_Lmt_FW_CC_N = <
				66	(-65535)	72	72	72	72	72	72	75	75	74	73	73	72	72	64
				73	66	64	64	65	65	64	65	69	69	67	66	66	66	66	66
				76	65	64	64	64	64	64	64	66	66	66	65	65	65	64	66
				69	66	65	65	65	65	65	65	67	66	66	66	66	66	66	68
				67	66	65	65	64	65	65	65	66	66	65	64	64	64	64	66
				68	66	66	66	66	66	66	66	68	67	67	66	66	66	66	67
				67	65	64	64	64	64	64	64	66	66	66	65	65	65	64	66
				69	66	66	66	66	66	66	66	67	66	67	66	66	66	66	67
				67	66	66	66	65	66	66	66	66	66	66	65	65	66	65	67
				69	66	66	66	66	66	66	66	67	67	67	66	66	66	66	66
				67	65	64	64	64	64	65	65	67	66	66	65	65	66	65	67
				68	64	64	65	64	64	65	66	66	66	66	64	64	64	64	68
				67	65	64	65	64	65	65	66	66	66	66	66	66	66	66	66
				67	66	66	66	66	66	66	67	67	67	67	66	66	66	66	67
				67	64	64	64	64	65	65	66	65	66	66	64	64	65	64	67
				68	66	66	66	66	66	66	67	66	66	66	66	66	66	66	68
				66	66	66	66	66	66	66	66	66	66	66	66	66	66	66	67
				68	66	66	66	66	66	66	67	67	67	67	66	66	66	66	68
				67	64	64	64	64	64	65	65	66	66	65	65	65	65	64	67
				67	66	66	66	66	66	66	67	67	67	66	66	66	66	66	69
				66	65	65	65	65	66	66	66	67	66	66	66	66	65	65	67
				67	66	66	66	66	66	66	66	68	67	67	66	66	67	67	69
				67	65	64	65	64	65	66	66	67	66	66	65	66	65	65	69
				68	66	66	66	66	66	66	67	67	66	66	66	66	66	66	69
				66	65	65	66	65	66	66	66	66	66	66	66	66	66	66	69
				68	66	66	66	66	67	67	68	67	67	66	67	66	67	67	69
				67	65	64	64	64	66	66	66	66	66	66	66	66	66	66	69
				69	66	66	66	66	67	66	67	66	66	66	66	66	66	66	70
				66	66	66	66	66	66	66	67	65	66	65	65	66	66	66	70
				67	67	67	66	66	68	67	68	66	66	66	66	66	66	67	70
				68	65	64	64	64	65	65	66	66	66	66	66	66	66	67	69
				69	66	66	66	66	67	66	67	66	66	66	66	66	67	67	71
				66	66	66	66	65	66	66	67	65	65	66	65	66	66	67	69
				68	66	66	67	66	67	68	68	66	66	66	67	66	67	68	78
				67	65	64	64	64	66	66	66	64	64	65	65	65	65	66	67
				64	72	72	72	72	74	75	75	73	72	73	73	73	73	75	69
				0 0 0>;

			PS_Config_Lmt_FW_Diff_P = <
				50	65535	50	50	50	50	50	50	50	50	50	50	50	50	50	50
				50	50	50	50	50	50	50	50	50	50	50	50	50	50	50	50
				50	50	50	50	50	50	50	50	50	50	50	50	50	50	50	50
				50	50	50	50	50	50	50	50	50	50	50	50	50	50	50	50
				50	50	50	50	50	50	50	50	50	50	50	50	50	50	50	50
				50	50	50	50	50	50	50	50	50	50	50	50	50	50	50	50
				50	50	50	50	50	50	50	50	50	50	50	50	50	50	50	50
				50	50	50	50	50	50	50	50	50	50	50	50	50	50	50	50
				50	50	50	50	50	50	50	50	50	50	50	50	50	50	50	50
				50	50	50	50	50	50	50	50	50	50	50	50	50	50	50	50
				50	50	50	50	50	50	50	50	50	50	50	50	50	50	50	50
				50	50	50	50	50	50	50	50	50	50	50	50	50	50	50	50
				50	50	50	50	50	50	50	50	50	50	50	50	50	50	50	50
				50	50	50	50	50	50	50	50	50	50	50	50	50	50	50	50
				50	50	50	50	50	50	50	50	50	50	50	50	50	50	50	50
				50	50	50	50	50	50	50	50	50	50	50	50	50	50	50	50
				50	50	50	50	50	50	50	50	50	50	50	50	50	50	50	50
				50	50	50	50	50	50	50	50	50	50	50	50	50	50	50	50
				50	50	50	50	50	50	50	50	50	50	50	50	50	50	50	50
				50	50	50	50	50	50	50	50	50	50	50	50	50	50	50	50
				50	50	50	50	50	50	50	50	50	50	50	50	50	50	50	50
				50	50	50	50	50	50	50	50	50	50	50	50	50	50	50	50
				50	50	50	50	50	50	50	50	50	50	50	50	50	50	50	50
				50	50	50	50	50	50	50	50	50	50	50	50	50	50	50	50
				50	50	50	50	50	50	50	50	50	50	50	50	50	50	50	50
				50	50	50	50	50	50	50	50	50	50	50	50	50	50	50	50
				50	50	50	50	50	50	50	50	50	50	50	50	50	50	50	50
				50	50	50	50	50	50	50	50	50	50	50	50	50	50	50	50
				50	50	50	50	50	50	50	50	50	50	50	50	50	50	50	50
				50	50	50	50	50	50	50	50	50	50	50	50	50	50	50	50
				50	50	50	50	50	50	50	50	50	50	50	50	50	50	50	50
				50	50	50	50	50	50	50	50	50	50	50	50	50	50	50	50
				50	50	50	50	50	50	50	50	50	50	50	50	50	50	50	50
				50	50	50	50	50	50	50	50	50	50	50	50	50	50	50	50
				50	50	50	50	50	50	50	50	50	50	50	50	50	50	50	50
				50	50	50	50	50	50	50	50	50	50	50	50	50	50	50	50
				75 75 75>;


			PS_Config_Lmt_FW_Diff_N = <
				 (-50)	(-65535)	(-50)	(-50)	(-50)	(-50)	(-50)	(-50)	(-50)	(-50)	(-50)	(-50)	(-50)	(-50)	(-50)	(-50)
				(-50)	(-50)	(-50)	(-50)	(-50)	(-50)	(-50)	(-50)	(-50)	(-50)	(-50)	(-50)	(-50)	(-50)	(-50)	(-50)
				(-50)	(-50)	(-50)	(-50)	(-50)	(-50)	(-50)	(-50)	(-50)	(-50)	(-50)	(-50)	(-50)	(-50)	(-50)	(-50)
				(-50)	(-50)	(-50)	(-50)	(-50)	(-50)	(-50)	(-50)	(-50)	(-50)	(-50)	(-50)	(-50)	(-50)	(-50)	(-50)
				(-50)	(-50)	(-50)	(-50)	(-50)	(-50)	(-50)	(-50)	(-50)	(-50)	(-50)	(-50)	(-50)	(-50)	(-50)	(-50)
				(-50)	(-50)	(-50)	(-50)	(-50)	(-50)	(-50)	(-50)	(-50)	(-50)	(-50)	(-50)	(-50)	(-50)	(-50)	(-50)
				(-50)	(-50)	(-50)	(-50)	(-50)	(-50)	(-50)	(-50)	(-50)	(-50)	(-50)	(-50)	(-50)	(-50)	(-50)	(-50)
				(-50)	(-50)	(-50)	(-50)	(-50)	(-50)	(-50)	(-50)	(-50)	(-50)	(-50)	(-50)	(-50)	(-50)	(-50)	(-50)
				(-50)	(-50)	(-50)	(-50)	(-50)	(-50)	(-50)	(-50)	(-50)	(-50)	(-50)	(-50)	(-50)	(-50)	(-50)	(-50)
				(-50)	(-50)	(-50)	(-50)	(-50)	(-50)	(-50)	(-50)	(-50)	(-50)	(-50)	(-50)	(-50)	(-50)	(-50)	(-50)
				(-50)	(-50)	(-50)	(-50)	(-50)	(-50)	(-50)	(-50)	(-50)	(-50)	(-50)	(-50)	(-50)	(-50)	(-50)	(-50)
				(-50)	(-50)	(-50)	(-50)	(-50)	(-50)	(-50)	(-50)	(-50)	(-50)	(-50)	(-50)	(-50)	(-50)	(-50)	(-50)
				(-50)	(-50)	(-50)	(-50)	(-50)	(-50)	(-50)	(-50)	(-50)	(-50)	(-50)	(-50)	(-50)	(-50)	(-50)	(-50)
				(-50)	(-50)	(-50)	(-50)	(-50)	(-50)	(-50)	(-50)	(-50)	(-50)	(-50)	(-50)	(-50)	(-50)	(-50)	(-50)
				(-50)	(-50)	(-50)	(-50)	(-50)	(-50)	(-50)	(-50)	(-50)	(-50)	(-50)	(-50)	(-50)	(-50)	(-50)	(-50)
				(-50)	(-50)	(-50)	(-50)	(-50)	(-50)	(-50)	(-50)	(-50)	(-50)	(-50)	(-50)	(-50)	(-50)	(-50)	(-50)
				(-50)	(-50)	(-50)	(-50)	(-50)	(-50)	(-50)	(-50)	(-50)	(-50)	(-50)	(-50)	(-50)	(-50)	(-50)	(-50)
				(-50)	(-50)	(-50)	(-50)	(-50)	(-50)	(-50)	(-50)	(-50)	(-50)	(-50)	(-50)	(-50)	(-50)	(-50)	(-50)
				(-50)	(-50)	(-50)	(-50)	(-50)	(-50)	(-50)	(-50)	(-50)	(-50)	(-50)	(-50)	(-50)	(-50)	(-50)	(-50)
				(-50)	(-50)	(-50)	(-50)	(-50)	(-50)	(-50)	(-50)	(-50)	(-50)	(-50)	(-50)	(-50)	(-50)	(-50)	(-50)
				(-50)	(-50)	(-50)	(-50)	(-50)	(-50)	(-50)	(-50)	(-50)	(-50)	(-50)	(-50)	(-50)	(-50)	(-50)	(-50)
				(-50)	(-50)	(-50)	(-50)	(-50)	(-50)	(-50)	(-50)	(-50)	(-50)	(-50)	(-50)	(-50)	(-50)	(-50)	(-50)
				(-50)	(-50)	(-50)	(-50)	(-50)	(-50)	(-50)	(-50)	(-50)	(-50)	(-50)	(-50)	(-50)	(-50)	(-50)	(-50)
				(-50)	(-50)	(-50)	(-50)	(-50)	(-50)	(-50)	(-50)	(-50)	(-50)	(-50)	(-50)	(-50)	(-50)	(-50)	(-50)
				(-50)	(-50)	(-50)	(-50)	(-50)	(-50)	(-50)	(-50)	(-50)	(-50)	(-50)	(-50)	(-50)	(-50)	(-50)	(-50)
				(-50)	(-50)	(-50)	(-50)	(-50)	(-50)	(-50)	(-50)	(-50)	(-50)	(-50)	(-50)	(-50)	(-50)	(-50)	(-50)
				(-50)	(-50)	(-50)	(-50)	(-50)	(-50)	(-50)	(-50)	(-50)	(-50)	(-50)	(-50)	(-50)	(-50)	(-50)	(-50)
				(-50)	(-50)	(-50)	(-50)	(-50)	(-50)	(-50)	(-50)	(-50)	(-50)	(-50)	(-50)	(-50)	(-50)	(-50)	(-50)
				(-50)	(-50)	(-50)	(-50)	(-50)	(-50)	(-50)	(-50)	(-50)	(-50)	(-50)	(-50)	(-50)	(-50)	(-50)	(-50)
				(-50)	(-50)	(-50)	(-50)	(-50)	(-50)	(-50)	(-50)	(-50)	(-50)	(-50)	(-50)	(-50)	(-50)	(-50)	(-50)
				(-50)	(-50)	(-50)	(-50)	(-50)	(-50)	(-50)	(-50)	(-50)	(-50)	(-50)	(-50)	(-50)	(-50)	(-50)	(-50)
				(-50)	(-50)	(-50)	(-50)	(-50)	(-50)	(-50)	(-50)	(-50)	(-50)	(-50)	(-50)	(-50)	(-50)	(-50)	(-50)
				(-50)	(-50)	(-50)	(-50)	(-50)	(-50)	(-50)	(-50)	(-50)	(-50)	(-50)	(-50)	(-50)	(-50)	(-50)	(-50)
				(-50)	(-50)	(-50)	(-50)	(-50)	(-50)	(-50)	(-50)	(-50)	(-50)	(-50)	(-50)	(-50)	(-50)	(-50)	(-50)
				(-50)	(-50)	(-50)	(-50)	(-50)	(-50)	(-50)	(-50)	(-50)	(-50)	(-50)	(-50)	(-50)	(-50)	(-50)	(-50)
				(-50)	(-50)	(-50)	(-50)	(-50)	(-50)	(-50)	(-50)	(-50)	(-50)	(-50)	(-50)	(-50)	(-50)	(-50)	(-50)
				(-75) (-75) (-75)>;

			PS_Config_Diff_Test_Frame = <50>;
		};

		/*for Xiaomi J15S 672D TM6.53" module*/
		novatek-mp-criteria-5948@0 {
			#address-cells = <1>;
			#size-cells = <0>;
			compatible = "novatek-mp-criteria-5948";

			/* MP Config */
			IC_X_CFG_SIZE = <16>;
			IC_Y_CFG_SIZE = <36>;
			IC_KEY_CFG_SIZE = <4>;
			X_Channel = <16>;
			Y_Channel = <36>;
			AIN_X = <0 1 2 3 4 5 6 7 8 9 10 11 12 13 14 15>;
			AIN_Y = <0 1 2 3 4 5 6 7 8 9 10 11 12 13 14 15 16 17
						18 19 20 21 22 23 24 25 26 27 28 29 30 31 32 33 34 35>;
			AIN_KEY = <0 1 2 0xFF>;

			/* MP Criteria */
			PS_Config_Lmt_Short_Rawdata_P = <
				14008 14008 14008 14008 14008 14008 14008 14008 14008 14008 14008 14008 14008 14008 14008 14008
				14008 14008 14008 14008 14008 14008 14008 14008 14008 14008 14008 14008 14008 14008 14008 14008
				14008 14008 14008 14008 14008 14008 14008 14008 14008 14008 14008 14008 14008 14008 14008 14008
				14008 14008 14008 14008 14008 14008 14008 14008 14008 14008 14008 14008 14008 14008 14008 14008
				14008 14008 14008 14008 14008 14008 14008 14008 14008 14008 14008 14008 14008 14008 14008 14008
				14008 14008 14008 14008 14008 14008 14008 14008 14008 14008 14008 14008 14008 14008 14008 14008
				14008 14008 14008 14008 14008 14008 14008 14008 14008 14008 14008 14008 14008 14008 14008 14008
				14008 14008 14008 14008 14008 14008 14008 14008 14008 14008 14008 14008 14008 14008 14008 14008
				14008 14008 14008 14008 14008 14008 14008 14008 14008 14008 14008 14008 14008 14008 14008 14008
				14008 14008 14008 14008 14008 14008 14008 14008 14008 14008 14008 14008 14008 14008 14008 14008
				14008 14008 14008 14008 14008 14008 14008 14008 14008 14008 14008 14008 14008 14008 14008 14008
				14008 14008 14008 14008 14008 14008 14008 14008 14008 14008 14008 14008 14008 14008 14008 14008
				14008 14008 14008 14008 14008 14008 14008 14008 14008 14008 14008 14008 14008 14008 14008 14008
				14008 14008 14008 14008 14008 14008 14008 14008 14008 14008 14008 14008 14008 14008 14008 14008
				14008 14008 14008 14008 14008 14008 14008 14008 14008 14008 14008 14008 14008 14008 14008 14008
				14008 14008 14008 14008 14008 14008 14008 14008 14008 14008 14008 14008 14008 14008 14008 14008
				14008 14008 14008 14008 14008 14008 14008 14008 14008 14008 14008 14008 14008 14008 14008 14008
				14008 14008 14008 14008 14008 14008 14008 14008 14008 14008 14008 14008 14008 14008 14008 14008
				14008 14008 14008 14008 14008 14008 14008 14008 14008 14008 14008 14008 14008 14008 14008 14008
				14008 14008 14008 14008 14008 14008 14008 14008 14008 14008 14008 14008 14008 14008 14008 14008
				14008 14008 14008 14008 14008 14008 14008 14008 14008 14008 14008 14008 14008 14008 14008 14008
				14008 14008 14008 14008 14008 14008 14008 14008 14008 14008 14008 14008 14008 14008 14008 14008
				14008 14008 14008 14008 14008 14008 14008 14008 14008 14008 14008 14008 14008 14008 14008 14008
				14008 14008 14008 14008 14008 14008 14008 14008 14008 14008 14008 14008 14008 14008 14008 14008
				14008 14008 14008 14008 14008 14008 14008 14008 14008 14008 14008 14008 14008 14008 14008 14008
				14008 14008 14008 14008 14008 14008 14008 14008 14008 14008 14008 14008 14008 14008 14008 14008
				14008 14008 14008 14008 14008 14008 14008 14008 14008 14008 14008 14008 14008 14008 14008 14008
				14008 14008 14008 14008 14008 14008 14008 14008 14008 14008 14008 14008 14008 14008 14008 14008
				14008 14008 14008 14008 14008 14008 14008 14008 14008 14008 14008 14008 14008 14008 14008 14008
				14008 14008 14008 14008 14008 14008 14008 14008 14008 14008 14008 14008 14008 14008 14008 14008
				14008 14008 14008 14008 14008 14008 14008 14008 14008 14008 14008 14008 14008 14008 14008 14008
				14008 14008 14008 14008 14008 14008 14008 14008 14008 14008 14008 14008 14008 14008 14008 14008
				14008 14008 14008 14008 14008 14008 14008 14008 14008 14008 14008 14008 14008 14008 14008 14008
				14008 14008 14008 14008 14008 14008 14008 14008 14008 14008 14008 14008 14008 14008 14008 14008
				14008 14008 14008 14008 14008 14008 14008 14008 14008 14008 14008 14008 14008 14008 14008 14008
				14008 14008 14008 14008 14008 14008 14008 14008 14008 14008 14008 14008 14008 14008 14008 14008
				14008 14008 14008>;

			PS_Config_Lmt_Short_Rawdata_N = <
				10000 10000 10000 10000 10000 10000 10000 10000 10000 10000 10000 10000 10000 10000 10000 10000
				10000 10000 10000 10000 10000 10000 10000 10000 10000 10000 10000 10000 10000 10000 10000 10000
				10000 10000 10000 10000 10000 10000 10000 10000 10000 10000 10000 10000 10000 10000 10000 10000
				10000 10000 10000 10000 10000 10000 10000 10000 10000 10000 10000 10000 10000 10000 10000 10000
				10000 10000 10000 10000 10000 10000 10000 10000 10000 10000 10000 10000 10000 10000 10000 10000
				10000 10000 10000 10000 10000 10000 10000 10000 10000 10000 10000 10000 10000 10000 10000 10000
				10000 10000 10000 10000 10000 10000 10000 10000 10000 10000 10000 10000 10000 10000 10000 10000
				10000 10000 10000 10000 10000 10000 10000 10000 10000 10000 10000 10000 10000 10000 10000 10000
				10000 10000 10000 10000 10000 10000 10000 10000 10000 10000 10000 10000 10000 10000 10000 10000
				10000 10000 10000 10000 10000 10000 10000 10000 10000 10000 10000 10000 10000 10000 10000 10000
				10000 10000 10000 10000 10000 10000 10000 10000 10000 10000 10000 10000 10000 10000 10000 10000
				10000 10000 10000 10000 10000 10000 10000 10000 10000 10000 10000 10000 10000 10000 10000 10000
				10000 10000 10000 10000 10000 10000 10000 10000 10000 10000 10000 10000 10000 10000 10000 10000
				10000 10000 10000 10000 10000 10000 10000 10000 10000 10000 10000 10000 10000 10000 10000 10000
				10000 10000 10000 10000 10000 10000 10000 10000 10000 10000 10000 10000 10000 10000 10000 10000
				10000 10000 10000 10000 10000 10000 10000 10000 10000 10000 10000 10000 10000 10000 10000 10000
				10000 10000 10000 10000 10000 10000 10000 10000 10000 10000 10000 10000 10000 10000 10000 10000
				10000 10000 10000 10000 10000 10000 10000 10000 10000 10000 10000 10000 10000 10000 10000 10000
				10000 10000 10000 10000 10000 10000 10000 10000 10000 10000 10000 10000 10000 10000 10000 10000
				10000 10000 10000 10000 10000 10000 10000 10000 10000 10000 10000 10000 10000 10000 10000 10000
				10000 10000 10000 10000 10000 10000 10000 10000 10000 10000 10000 10000 10000 10000 10000 10000
				10000 10000 10000 10000 10000 10000 10000 10000 10000 10000 10000 10000 10000 10000 10000 10000
				10000 10000 10000 10000 10000 10000 10000 10000 10000 10000 10000 10000 10000 10000 10000 10000
				10000 10000 10000 10000 10000 10000 10000 10000 10000 10000 10000 10000 10000 10000 10000 10000
				10000 10000 10000 10000 10000 10000 10000 10000 10000 10000 10000 10000 10000 10000 10000 10000
				10000 10000 10000 10000 10000 10000 10000 10000 10000 10000 10000 10000 10000 10000 10000 10000
				10000 10000 10000 10000 10000 10000 10000 10000 10000 10000 10000 10000 10000 10000 10000 10000
				10000 10000 10000 10000 10000 10000 10000 10000 10000 10000 10000 10000 10000 10000 10000 10000
				10000 10000 10000 10000 10000 10000 10000 10000 10000 10000 10000 10000 10000 10000 10000 10000
				10000 10000 10000 10000 10000 10000 10000 10000 10000 10000 10000 10000 10000 10000 10000 10000
				10000 10000 10000 10000 10000 10000 10000 10000 10000 10000 10000 10000 10000 10000 10000 10000
				10000 10000 10000 10000 10000 10000 10000 10000 10000 10000 10000 10000 10000 10000 10000 10000
				10000 10000 10000 10000 10000 10000 10000 10000 10000 10000 10000 10000 10000 10000 10000 10000
				10000 10000 10000 10000 10000 10000 10000 10000 10000 10000 10000 10000 10000 10000 10000 10000
				10000 10000 10000 10000 10000 10000 10000 10000 10000 10000 10000 10000 10000 10000 10000 10000
				10000 10000 10000 10000 10000 10000 10000 10000 10000 10000 10000 10000 10000 10000 10000 10000
				10000 10000 10000>;

			PS_Config_Lmt_Open_Rawdata_P = <
				5120 5120 5120 5120 5120 5120 5120 5120 5120 5120 5120 5120 5120 5120 5120 5120
				5120 5120 5120 5120 5120 5120 5120 5120 5120 5120 5120 5120 5120 5120 5120 5120
				5120 5120 5120 5120 5120 5120 5120 5120 5120 5120 5120 5120 5120 5120 5120 5120
				5120 5120 5120 5120 5120 5120 5120 5120 5120 5120 5120 5120 5120 5120 5120 5120
				5120 5120 5120 5120 5120 5120 5120 5120 5120 5120 5120 5120 5120 5120 5120 5120
				5120 5120 5120 5120 5120 5120 5120 5120 5120 5120 5120 5120 5120 5120 5120 5120
				5120 5120 5120 5120 5120 5120 5120 5120 5120 5120 5120 5120 5120 5120 5120 5120
				5120 5120 5120 5120 5120 5120 5120 5120 5120 5120 5120 5120 5120 5120 5120 5120
				5120 5120 5120 5120 5120 5120 5120 5120 5120 5120 5120 5120 5120 5120 5120 5120
				5120 5120 5120 5120 5120 5120 5120 5120 5120 5120 5120 5120 5120 5120 5120 5120
				5120 5120 5120 5120 5120 5120 5120 5120 5120 5120 5120 5120 5120 5120 5120 5120
				5120 5120 5120 5120 5120 5120 5120 5120 5120 5120 5120 5120 5120 5120 5120 5120
				5120 5120 5120 5120 5120 5120 5120 5120 5120 5120 5120 5120 5120 5120 5120 5120
				5120 5120 5120 5120 5120 5120 5120 5120 5120 5120 5120 5120 5120 5120 5120 5120
				5120 5120 5120 5120 5120 5120 5120 5120 5120 5120 5120 5120 5120 5120 5120 5120
				5120 5120 5120 5120 5120 5120 5120 5120 5120 5120 5120 5120 5120 5120 5120 5120
				5120 5120 5120 5120 5120 5120 5120 5120 5120 5120 5120 5120 5120 5120 5120 5120
				5120 5120 5120 5120 5120 5120 5120 5120 5120 5120 5120 5120 5120 5120 5120 5120
				5120 5120 5120 5120 5120 5120 5120 5120 5120 5120 5120 5120 5120 5120 5120 5120
				5120 5120 5120 5120 5120 5120 5120 5120 5120 5120 5120 5120 5120 5120 5120 5120
				5120 5120 5120 5120 5120 5120 5120 5120 5120 5120 5120 5120 5120 5120 5120 5120
				5120 5120 5120 5120 5120 5120 5120 5120 5120 5120 5120 5120 5120 5120 5120 5120
				5120 5120 5120 5120 5120 5120 5120 5120 5120 5120 5120 5120 5120 5120 5120 5120
				5120 5120 5120 5120 5120 5120 5120 5120 5120 5120 5120 5120 5120 5120 5120 5120
				5120 5120 5120 5120 5120 5120 5120 5120 5120 5120 5120 5120 5120 5120 5120 5120
				5120 5120 5120 5120 5120 5120 5120 5120 5120 5120 5120 5120 5120 5120 5120 5120
				5120 5120 5120 5120 5120 5120 5120 5120 5120 5120 5120 5120 5120 5120 5120 5120
				5120 5120 5120 5120 5120 5120 5120 5120 5120 5120 5120 5120 5120 5120 5120 5120
				5120 5120 5120 5120 5120 5120 5120 5120 5120 5120 5120 5120 5120 5120 5120 5120
				5120 5120 5120 5120 5120 5120 5120 5120 5120 5120 5120 5120 5120 5120 5120 5120
				5120 5120 5120 5120 5120 5120 5120 5120 5120 5120 5120 5120 5120 5120 5120 5120
				5120 5120 5120 5120 5120 5120 5120 5120 5120 5120 5120 5120 5120 5120 5120 5120
				5120 5120 5120 5120 5120 5120 5120 5120 5120 5120 5120 5120 5120 5120 5120 5120
				5120 5120 5120 5120 5120 5120 5120 5120 5120 5120 5120 5120 5120 5120 5120 5120
				5120 5120 5120 5120 5120 5120 5120 5120 5120 5120 5120 5120 5120 5120 5120 5120
				5120 5120 5120 5120 5120 5120 5120 5120 5120 5120 5120 5120 5120 5120 5120 5120
				5120 5120 5120>;

			PS_Config_Lmt_Open_Rawdata_N = <
				(-511) (-511) (-511) (-511) (-511) (-511) (-511) (-511) (-511) (-511) (-511) (-511) (-511) (-511) (-511) (-511)
				(-511) (-511) (-511) (-511) (-511) (-511) (-511) (-511) (-511) (-511) (-511) (-511) (-511) (-511) (-511) (-511)
				(-511) (-511) (-511) (-511) (-511) (-511) (-511) (-511) (-511) (-511) (-511) (-511) (-511) (-511) (-511) (-511)
				(-511) (-511) (-511) (-511) (-511) (-511) (-511) (-511) (-511) (-511) (-511) (-511) (-511) (-511) (-511) (-511)
				(-511) (-511) (-511) (-511) (-511) (-511) (-511) (-511) (-511) (-511) (-511) (-511) (-511) (-511) (-511) (-511)
				(-511) (-511) (-511) (-511) (-511) (-511) (-511) (-511) (-511) (-511) (-511) (-511) (-511) (-511) (-511) (-511)
				(-511) (-511) (-511) (-511) (-511) (-511) (-511) (-511) (-511) (-511) (-511) (-511) (-511) (-511) (-511) (-511)
				(-511) (-511) (-511) (-511) (-511) (-511) (-511) (-511) (-511) (-511) (-511) (-511) (-511) (-511) (-511) (-511)
				(-511) (-511) (-511) (-511) (-511) (-511) (-511) (-511) (-511) (-511) (-511) (-511) (-511) (-511) (-511) (-511)
				(-511) (-511) (-511) (-511) (-511) (-511) (-511) (-511) (-511) (-511) (-511) (-511) (-511) (-511) (-511) (-511)
				(-511) (-511) (-511) (-511) (-511) (-511) (-511) (-511) (-511) (-511) (-511) (-511) (-511) (-511) (-511) (-511)
				(-511) (-511) (-511) (-511) (-511) (-511) (-511) (-511) (-511) (-511) (-511) (-511) (-511) (-511) (-511) (-511)
				(-511) (-511) (-511) (-511) (-511) (-511) (-511) (-511) (-511) (-511) (-511) (-511) (-511) (-511) (-511) (-511)
				(-511) (-511) (-511) (-511) (-511) (-511) (-511) (-511) (-511) (-511) (-511) (-511) (-511) (-511) (-511) (-511)
				(-511) (-511) (-511) (-511) (-511) (-511) (-511) (-511) (-511) (-511) (-511) (-511) (-511) (-511) (-511) (-511)
				(-511) (-511) (-511) (-511) (-511) (-511) (-511) (-511) (-511) (-511) (-511) (-511) (-511) (-511) (-511) (-511)
				(-511) (-511) (-511) (-511) (-511) (-511) (-511) (-511) (-511) (-511) (-511) (-511) (-511) (-511) (-511) (-511)
				(-511) (-511) (-511) (-511) (-511) (-511) (-511) (-511) (-511) (-511) (-511) (-511) (-511) (-511) (-511) (-511)
				(-511) (-511) (-511) (-511) (-511) (-511) (-511) (-511) (-511) (-511) (-511) (-511) (-511) (-511) (-511) (-511)
				(-511) (-511) (-511) (-511) (-511) (-511) (-511) (-511) (-511) (-511) (-511) (-511) (-511) (-511) (-511) (-511)
				(-511) (-511) (-511) (-511) (-511) (-511) (-511) (-511) (-511) (-511) (-511) (-511) (-511) (-511) (-511) (-511)
				(-511) (-511) (-511) (-511) (-511) (-511) (-511) (-511) (-511) (-511) (-511) (-511) (-511) (-511) (-511) (-511)
				(-511) (-511) (-511) (-511) (-511) (-511) (-511) (-511) (-511) (-511) (-511) (-511) (-511) (-511) (-511) (-511)
				(-511) (-511) (-511) (-511) (-511) (-511) (-511) (-511) (-511) (-511) (-511) (-511) (-511) (-511) (-511) (-511)
				(-511) (-511) (-511) (-511) (-511) (-511) (-511) (-511) (-511) (-511) (-511) (-511) (-511) (-511) (-511) (-511)
				(-511) (-511) (-511) (-511) (-511) (-511) (-511) (-511) (-511) (-511) (-511) (-511) (-511) (-511) (-511) (-511)
				(-511) (-511) (-511) (-511) (-511) (-511) (-511) (-511) (-511) (-511) (-511) (-511) (-511) (-511) (-511) (-511)
				(-511) (-511) (-511) (-511) (-511) (-511) (-511) (-511) (-511) (-511) (-511) (-511) (-511) (-511) (-511) (-511)
				(-511) (-511) (-511) (-511) (-511) (-511) (-511) (-511) (-511) (-511) (-511) (-511) (-511) (-511) (-511) (-511)
				(-511) (-511) (-511) (-511) (-511) (-511) (-511) (-511) (-511) (-511) (-511) (-511) (-511) (-511) (-511) (-511)
				(-511) (-511) (-511) (-511) (-511) (-511) (-511) (-511) (-511) (-511) (-511) (-511) (-511) (-511) (-511) (-511)
				(-511) (-511) (-511) (-511) (-511) (-511) (-511) (-511) (-511) (-511) (-511) (-511) (-511) (-511) (-511) (-511)
				(-511) (-511) (-511) (-511) (-511) (-511) (-511) (-511) (-511) (-511) (-511) (-511) (-511) (-511) (-511) (-511)
				(-511) (-511) (-511) (-511) (-511) (-511) (-511) (-511) (-511) (-511) (-511) (-511) (-511) (-511) (-511) (-511)
				(-511) (-511) (-511) (-511) (-511) (-511) (-511) (-511) (-511) (-511) (-511) (-511) (-511) (-511) (-511) (-511)
				(-511) (-511) (-511) (-511) (-511) (-511) (-511) (-511) (-511) (-511) (-511) (-511) (-511) (-511) (-511) (-511)
				(-511) (-511) (-511)>;

			PS_Config_Lmt_FW_Rawdata_P = <
				2560 2560 2560 2560 2560 2560 2560 2560 2560 2560 2560 2560 2560 2560 2560 2560
				2560 2560 2560 2560 2560 2560 2560 2560 2560 2560 2560 2560 2560 2560 2560 2560
				2560 2560 2560 2560 2560 2560 2560 2560 2560 2560 2560 2560 2560 2560 2560 2560
				2560 2560 2560 2560 2560 2560 2560 2560 2560 2560 2560 2560 2560 2560 2560 2560
				2560 2560 2560 2560 2560 2560 2560 2560 2560 2560 2560 2560 2560 2560 2560 2560
				2560 2560 2560 2560 2560 2560 2560 2560 2560 2560 2560 2560 2560 2560 2560 2560
				2560 2560 2560 2560 2560 2560 2560 2560 2560 2560 2560 2560 2560 2560 2560 2560
				2560 2560 2560 2560 2560 2560 2560 2560 2560 2560 2560 2560 2560 2560 2560 2560
				2560 2560 2560 2560 2560 2560 2560 2560 2560 2560 2560 2560 2560 2560 2560 2560
				2560 2560 2560 2560 2560 2560 2560 2560 2560 2560 2560 2560 2560 2560 2560 2560
				2560 2560 2560 2560 2560 2560 2560 2560 2560 2560 2560 2560 2560 2560 2560 2560
				2560 2560 2560 2560 2560 2560 2560 2560 2560 2560 2560 2560 2560 2560 2560 2560
				2560 2560 2560 2560 2560 2560 2560 2560 2560 2560 2560 2560 2560 2560 2560 2560
				2560 2560 2560 2560 2560 2560 2560 2560 2560 2560 2560 2560 2560 2560 2560 2560
				2560 2560 2560 2560 2560 2560 2560 2560 2560 2560 2560 2560 2560 2560 2560 2560
				2560 2560 2560 2560 2560 2560 2560 2560 2560 2560 2560 2560 2560 2560 2560 2560
				2560 2560 2560 2560 2560 2560 2560 2560 2560 2560 2560 2560 2560 2560 2560 2560
				2560 2560 2560 2560 2560 2560 2560 2560 2560 2560 2560 2560 2560 2560 2560 2560
				2560 2560 2560 2560 2560 2560 2560 2560 2560 2560 2560 2560 2560 2560 2560 2560
				2560 2560 2560 2560 2560 2560 2560 2560 2560 2560 2560 2560 2560 2560 2560 2560
				2560 2560 2560 2560 2560 2560 2560 2560 2560 2560 2560 2560 2560 2560 2560 2560
				2560 2560 2560 2560 2560 2560 2560 2560 2560 2560 2560 2560 2560 2560 2560 2560
				2560 2560 2560 2560 2560 2560 2560 2560 2560 2560 2560 2560 2560 2560 2560 2560
				2560 2560 2560 2560 2560 2560 2560 2560 2560 2560 2560 2560 2560 2560 2560 2560
				2560 2560 2560 2560 2560 2560 2560 2560 2560 2560 2560 2560 2560 2560 2560 2560
				2560 2560 2560 2560 2560 2560 2560 2560 2560 2560 2560 2560 2560 2560 2560 2560
				2560 2560 2560 2560 2560 2560 2560 2560 2560 2560 2560 2560 2560 2560 2560 2560
				2560 2560 2560 2560 2560 2560 2560 2560 2560 2560 2560 2560 2560 2560 2560 2560
				2560 2560 2560 2560 2560 2560 2560 2560 2560 2560 2560 2560 2560 2560 2560 2560
				2560 2560 2560 2560 2560 2560 2560 2560 2560 2560 2560 2560 2560 2560 2560 2560
				2560 2560 2560 2560 2560 2560 2560 2560 2560 2560 2560 2560 2560 2560 2560 2560
				2560 2560 2560 2560 2560 2560 2560 2560 2560 2560 2560 2560 2560 2560 2560 2560
				2560 2560 2560 2560 2560 2560 2560 2560 2560 2560 2560 2560 2560 2560 2560 2560
				2560 2560 2560 2560 2560 2560 2560 2560 2560 2560 2560 2560 2560 2560 2560 2560
				2560 2560 2560 2560 2560 2560 2560 2560 2560 2560 2560 2560 2560 2560 2560 2560
				2560 2560 2560 2560 2560 2560 2560 2560 2560 2560 2560 2560 2560 2560 2560 2560
				2560 2560 2560>;

			PS_Config_Lmt_FW_Rawdata_N = <
				240 240 240 240 240 240 240 240 240 240 240 240 240 240 240 240
				240 240 240 240 240 240 240 240 240 240 240 240 240 240 240 240
				240 240 240 240 240 240 240 240 240 240 240 240 240 240 240 240
				240 240 240 240 240 240 240 240 240 240 240 240 240 240 240 240
				240 240 240 240 240 240 240 240 240 240 240 240 240 240 240 240
				240 240 240 240 240 240 240 240 240 240 240 240 240 240 240 240
				240 240 240 240 240 240 240 240 240 240 240 240 240 240 240 240
				240 240 240 240 240 240 240 240 240 240 240 240 240 240 240 240
				240 240 240 240 240 240 240 240 240 240 240 240 240 240 240 240
				240 240 240 240 240 240 240 240 240 240 240 240 240 240 240 240
				240 240 240 240 240 240 240 240 240 240 240 240 240 240 240 240
				240 240 240 240 240 240 240 240 240 240 240 240 240 240 240 240
				240 240 240 240 240 240 240 240 240 240 240 240 240 240 240 240
				240 240 240 240 240 240 240 240 240 240 240 240 240 240 240 240
				240 240 240 240 240 240 240 240 240 240 240 240 240 240 240 240
				240 240 240 240 240 240 240 240 240 240 240 240 240 240 240 240
				240 240 240 240 240 240 240 240 240 240 240 240 240 240 240 240
				240 240 240 240 240 240 240 240 240 240 240 240 240 240 240 240
				240 240 240 240 240 240 240 240 240 240 240 240 240 240 240 240
				240 240 240 240 240 240 240 240 240 240 240 240 240 240 240 240
				240 240 240 240 240 240 240 240 240 240 240 240 240 240 240 240
				240 240 240 240 240 240 240 240 240 240 240 240 240 240 240 240
				240 240 240 240 240 240 240 240 240 240 240 240 240 240 240 240
				240 240 240 240 240 240 240 240 240 240 240 240 240 240 240 240
				240 240 240 240 240 240 240 240 240 240 240 240 240 240 240 240
				240 240 240 240 240 240 240 240 240 240 240 240 240 240 240 240
				240 240 240 240 240 240 240 240 240 240 240 240 240 240 240 240
				240 240 240 240 240 240 240 240 240 240 240 240 240 240 240 240
				240 240 240 240 240 240 240 240 240 240 240 240 240 240 240 240
				240 240 240 240 240 240 240 240 240 240 240 240 240 240 240 240
				240 240 240 240 240 240 240 240 240 240 240 240 240 240 240 240
				240 240 240 240 240 240 240 240 240 240 240 240 240 240 240 240
				240 240 240 240 240 240 240 240 240 240 240 240 240 240 240 240
				240 240 240 240 240 240 240 240 240 240 240 240 240 240 240 240
				240 240 240 240 240 240 240 240 240 240 240 240 240 240 240 240
				240 240 240 240 240 240 240 240 240 240 240 240 240 240 240 240
				240 240 240>;

			PS_Config_Lmt_FW_CC_P = <
				314 314 314 314 314 314 314 314 314 314 314 314 314 314 314 314
				314 314 314 314 314 314 314 314 314 314 314 314 314 314 314 314
				314 314 314 314 314 314 314 314 314 314 314 314 314 314 314 314
				314 314 314 314 314 314 314 314 314 314 314 314 314 314 314 314
				314 314 314 314 314 314 314 314 314 314 314 314 314 314 314 314
				314 314 314 314 314 314 314 314 314 314 314 314 314 314 314 314
				314 314 314 314 314 314 314 314 314 314 314 314 314 314 314 314
				314 314 314 314 314 314 314 314 314 314 314 314 314 314 314 314
				314 314 314 314 314 314 314 314 314 314 314 314 314 314 314 314
				314 314 314 314 314 314 314 314 314 314 314 314 314 314 314 314
				314 314 314 314 314 314 314 314 314 314 314 314 314 314 314 314
				314 314 314 314 314 314 314 314 314 314 314 314 314 314 314 314
				314 314 314 314 314 314 314 314 314 314 314 314 314 314 314 314
				314 314 314 314 314 314 314 314 314 314 314 314 314 314 314 314
				314 314 314 314 314 314 314 314 314 314 314 314 314 314 314 314
				314 314 314 314 314 314 314 314 314 314 314 314 314 314 314 314
				314 314 314 314 314 314 314 314 314 314 314 314 314 314 314 314
				314 314 314 314 314 314 314 314 314 314 314 314 314 314 314 314
				314 314 314 314 314 314 314 314 314 314 314 314 314 314 314 314
				314 314 314 314 314 314 314 314 314 314 314 314 314 314 314 314
				314 314 314 314 314 314 314 314 314 314 314 314 314 314 314 314
				314 314 314 314 314 314 314 314 314 314 314 314 314 314 314 314
				314 314 314 314 314 314 314 314 314 314 314 314 314 314 314 314
				314 314 314 314 314 314 314 314 314 314 314 314 314 314 314 314
				314 314 314 314 314 314 314 314 314 314 314 314 314 314 314 314
				314 314 314 314 314 314 314 314 314 314 314 314 314 314 314 314
				314 314 314 314 314 314 314 314 314 314 314 314 314 314 314 314
				314 314 314 314 314 314 314 314 314 314 314 314 314 314 314 314
				314 314 314 314 314 314 314 314 314 314 314 314 314 314 314 314
				314 314 314 314 314 314 314 314 314 314 314 314 314 314 314 314
				314 314 314 314 314 314 314 314 314 314 314 314 314 314 314 314
				314 314 314 314 314 314 314 314 314 314 314 314 314 314 314 314
				314 314 314 314 314 314 314 314 314 314 314 314 314 314 314 314
				314 314 314 314 314 314 314 314 314 314 314 314 314 314 314 314
				314 314 314 314 314 314 314 314 314 314 314 314 314 314 314 314
				314 314 314 314 314 314 314 314 314 314 314 314 314 314 314 314
				314 314 314>;

			PS_Config_Lmt_FW_CC_N = <
				0 0 0 0 0 0 0 0 0 0 0 0 0 0 0 0
				0 0 0 0 0 0 0 0 0 0 0 0 0 0 0 0
				0 0 0 0 0 0 0 0 0 0 0 0 0 0 0 0
				0 0 0 0 0 0 0 0 0 0 0 0 0 0 0 0
				0 0 0 0 0 0 0 0 0 0 0 0 0 0 0 0
				0 0 0 0 0 0 0 0 0 0 0 0 0 0 0 0
				0 0 0 0 0 0 0 0 0 0 0 0 0 0 0 0
				0 0 0 0 0 0 0 0 0 0 0 0 0 0 0 0
				0 0 0 0 0 0 0 0 0 0 0 0 0 0 0 0
				0 0 0 0 0 0 0 0 0 0 0 0 0 0 0 0
				0 0 0 0 0 0 0 0 0 0 0 0 0 0 0 0
				0 0 0 0 0 0 0 0 0 0 0 0 0 0 0 0
				0 0 0 0 0 0 0 0 0 0 0 0 0 0 0 0
				0 0 0 0 0 0 0 0 0 0 0 0 0 0 0 0
				0 0 0 0 0 0 0 0 0 0 0 0 0 0 0 0
				0 0 0 0 0 0 0 0 0 0 0 0 0 0 0 0
				0 0 0 0 0 0 0 0 0 0 0 0 0 0 0 0
				0 0 0 0 0 0 0 0 0 0 0 0 0 0 0 0
				0 0 0 0 0 0 0 0 0 0 0 0 0 0 0 0
				0 0 0 0 0 0 0 0 0 0 0 0 0 0 0 0
				0 0 0 0 0 0 0 0 0 0 0 0 0 0 0 0
				0 0 0 0 0 0 0 0 0 0 0 0 0 0 0 0
				0 0 0 0 0 0 0 0 0 0 0 0 0 0 0 0
				0 0 0 0 0 0 0 0 0 0 0 0 0 0 0 0
				0 0 0 0 0 0 0 0 0 0 0 0 0 0 0 0
				0 0 0 0 0 0 0 0 0 0 0 0 0 0 0 0
				0 0 0 0 0 0 0 0 0 0 0 0 0 0 0 0
				0 0 0 0 0 0 0 0 0 0 0 0 0 0 0 0
				0 0 0 0 0 0 0 0 0 0 0 0 0 0 0 0
				0 0 0 0 0 0 0 0 0 0 0 0 0 0 0 0
				0 0 0 0 0 0 0 0 0 0 0 0 0 0 0 0
				0 0 0 0 0 0 0 0 0 0 0 0 0 0 0 0
				0 0 0 0 0 0 0 0 0 0 0 0 0 0 0 0
				0 0 0 0 0 0 0 0 0 0 0 0 0 0 0 0
				0 0 0 0 0 0 0 0 0 0 0 0 0 0 0 0
				0 0 0 0 0 0 0 0 0 0 0 0 0 0 0 0
				0 0 0>;

			PS_Config_Lmt_FW_Diff_P = <
				75 75 75 75 75 75 75 75 75 75 75 75 75 75 75 75
				75 75 75 75 75 75 75 75 75 75 75 75 75 75 75 75
				75 75 75 75 75 75 75 75 75 75 75 75 75 75 75 75
				75 75 75 75 75 75 75 75 75 75 75 75 75 75 75 75
				75 75 75 75 75 75 75 75 75 75 75 75 75 75 75 75
				75 75 75 75 75 75 75 75 75 75 75 75 75 75 75 75
				75 75 75 75 75 75 75 75 75 75 75 75 75 75 75 75
				75 75 75 75 75 75 75 75 75 75 75 75 75 75 75 75
				75 75 75 75 75 75 75 75 75 75 75 75 75 75 75 75
				75 75 75 75 75 75 75 75 75 75 75 75 75 75 75 75
				75 75 75 75 75 75 75 75 75 75 75 75 75 75 75 75
				75 75 75 75 75 75 75 75 75 75 75 75 75 75 75 75
				75 75 75 75 75 75 75 75 75 75 75 75 75 75 75 75
				75 75 75 75 75 75 75 75 75 75 75 75 75 75 75 75
				75 75 75 75 75 75 75 75 75 75 75 75 75 75 75 75
				75 75 75 75 75 75 75 75 75 75 75 75 75 75 75 75
				75 75 75 75 75 75 75 75 75 75 75 75 75 75 75 75
				75 75 75 75 75 75 75 75 75 75 75 75 75 75 75 75
				75 75 75 75 75 75 75 75 75 75 75 75 75 75 75 75
				75 75 75 75 75 75 75 75 75 75 75 75 75 75 75 75
				75 75 75 75 75 75 75 75 75 75 75 75 75 75 75 75
				75 75 75 75 75 75 75 75 75 75 75 75 75 75 75 75
				75 75 75 75 75 75 75 75 75 75 75 75 75 75 75 75
				75 75 75 75 75 75 75 75 75 75 75 75 75 75 75 75
				75 75 75 75 75 75 75 75 75 75 75 75 75 75 75 75
				75 75 75 75 75 75 75 75 75 75 75 75 75 75 75 75
				75 75 75 75 75 75 75 75 75 75 75 75 75 75 75 75
				75 75 75 75 75 75 75 75 75 75 75 75 75 75 75 75
				75 75 75 75 75 75 75 75 75 75 75 75 75 75 75 75
				75 75 75 75 75 75 75 75 75 75 75 75 75 75 75 75
				75 75 75 75 75 75 75 75 75 75 75 75 75 75 75 75
				75 75 75 75 75 75 75 75 75 75 75 75 75 75 75 75
				75 75 75 75 75 75 75 75 75 75 75 75 75 75 75 75
				75 75 75 75 75 75 75 75 75 75 75 75 75 75 75 75
				75 75 75 75 75 75 75 75 75 75 75 75 75 75 75 75
				75 75 75 75 75 75 75 75 75 75 75 75 75 75 75 75
				75 75 75>;

			PS_Config_Lmt_FW_Diff_N = <
				(-75) (-75) (-75) (-75) (-75) (-75) (-75) (-75) (-75) (-75) (-75) (-75) (-75) (-75) (-75) (-75)
				(-75) (-75) (-75) (-75) (-75) (-75) (-75) (-75) (-75) (-75) (-75) (-75) (-75) (-75) (-75) (-75)
				(-75) (-75) (-75) (-75) (-75) (-75) (-75) (-75) (-75) (-75) (-75) (-75) (-75) (-75) (-75) (-75)
				(-75) (-75) (-75) (-75) (-75) (-75) (-75) (-75) (-75) (-75) (-75) (-75) (-75) (-75) (-75) (-75)
				(-75) (-75) (-75) (-75) (-75) (-75) (-75) (-75) (-75) (-75) (-75) (-75) (-75) (-75) (-75) (-75)
				(-75) (-75) (-75) (-75) (-75) (-75) (-75) (-75) (-75) (-75) (-75) (-75) (-75) (-75) (-75) (-75)
				(-75) (-75) (-75) (-75) (-75) (-75) (-75) (-75) (-75) (-75) (-75) (-75) (-75) (-75) (-75) (-75)
				(-75) (-75) (-75) (-75) (-75) (-75) (-75) (-75) (-75) (-75) (-75) (-75) (-75) (-75) (-75) (-75)
				(-75) (-75) (-75) (-75) (-75) (-75) (-75) (-75) (-75) (-75) (-75) (-75) (-75) (-75) (-75) (-75)
				(-75) (-75) (-75) (-75) (-75) (-75) (-75) (-75) (-75) (-75) (-75) (-75) (-75) (-75) (-75) (-75)
				(-75) (-75) (-75) (-75) (-75) (-75) (-75) (-75) (-75) (-75) (-75) (-75) (-75) (-75) (-75) (-75)
				(-75) (-75) (-75) (-75) (-75) (-75) (-75) (-75) (-75) (-75) (-75) (-75) (-75) (-75) (-75) (-75)
				(-75) (-75) (-75) (-75) (-75) (-75) (-75) (-75) (-75) (-75) (-75) (-75) (-75) (-75) (-75) (-75)
				(-75) (-75) (-75) (-75) (-75) (-75) (-75) (-75) (-75) (-75) (-75) (-75) (-75) (-75) (-75) (-75)
				(-75) (-75) (-75) (-75) (-75) (-75) (-75) (-75) (-75) (-75) (-75) (-75) (-75) (-75) (-75) (-75)
				(-75) (-75) (-75) (-75) (-75) (-75) (-75) (-75) (-75) (-75) (-75) (-75) (-75) (-75) (-75) (-75)
				(-75) (-75) (-75) (-75) (-75) (-75) (-75) (-75) (-75) (-75) (-75) (-75) (-75) (-75) (-75) (-75)
				(-75) (-75) (-75) (-75) (-75) (-75) (-75) (-75) (-75) (-75) (-75) (-75) (-75) (-75) (-75) (-75)
				(-75) (-75) (-75) (-75) (-75) (-75) (-75) (-75) (-75) (-75) (-75) (-75) (-75) (-75) (-75) (-75)
				(-75) (-75) (-75) (-75) (-75) (-75) (-75) (-75) (-75) (-75) (-75) (-75) (-75) (-75) (-75) (-75)
				(-75) (-75) (-75) (-75) (-75) (-75) (-75) (-75) (-75) (-75) (-75) (-75) (-75) (-75) (-75) (-75)
				(-75) (-75) (-75) (-75) (-75) (-75) (-75) (-75) (-75) (-75) (-75) (-75) (-75) (-75) (-75) (-75)
				(-75) (-75) (-75) (-75) (-75) (-75) (-75) (-75) (-75) (-75) (-75) (-75) (-75) (-75) (-75) (-75)
				(-75) (-75) (-75) (-75) (-75) (-75) (-75) (-75) (-75) (-75) (-75) (-75) (-75) (-75) (-75) (-75)
				(-75) (-75) (-75) (-75) (-75) (-75) (-75) (-75) (-75) (-75) (-75) (-75) (-75) (-75) (-75) (-75)
				(-75) (-75) (-75) (-75) (-75) (-75) (-75) (-75) (-75) (-75) (-75) (-75) (-75) (-75) (-75) (-75)
				(-75) (-75) (-75) (-75) (-75) (-75) (-75) (-75) (-75) (-75) (-75) (-75) (-75) (-75) (-75) (-75)
				(-75) (-75) (-75) (-75) (-75) (-75) (-75) (-75) (-75) (-75) (-75) (-75) (-75) (-75) (-75) (-75)
				(-75) (-75) (-75) (-75) (-75) (-75) (-75) (-75) (-75) (-75) (-75) (-75) (-75) (-75) (-75) (-75)
				(-75) (-75) (-75) (-75) (-75) (-75) (-75) (-75) (-75) (-75) (-75) (-75) (-75) (-75) (-75) (-75)
				(-75) (-75) (-75) (-75) (-75) (-75) (-75) (-75) (-75) (-75) (-75) (-75) (-75) (-75) (-75) (-75)
				(-75) (-75) (-75) (-75) (-75) (-75) (-75) (-75) (-75) (-75) (-75) (-75) (-75) (-75) (-75) (-75)
				(-75) (-75) (-75) (-75) (-75) (-75) (-75) (-75) (-75) (-75) (-75) (-75) (-75) (-75) (-75) (-75)
				(-75) (-75) (-75) (-75) (-75) (-75) (-75) (-75) (-75) (-75) (-75) (-75) (-75) (-75) (-75) (-75)
				(-75) (-75) (-75) (-75) (-75) (-75) (-75) (-75) (-75) (-75) (-75) (-75) (-75) (-75) (-75) (-75)
				(-75) (-75) (-75) (-75) (-75) (-75) (-75) (-75) (-75) (-75) (-75) (-75) (-75) (-75) (-75) (-75)
				(-75) (-75) (-75)>;

			PS_Config_Diff_Test_Frame = <50>;
		};
	};
};

#include <merlin/cust.dtsi>

#include "mediatek/cust_mt6768_camera.dtsi"
/*End of this file, DO NOT ADD ANYTHING HERE*/
